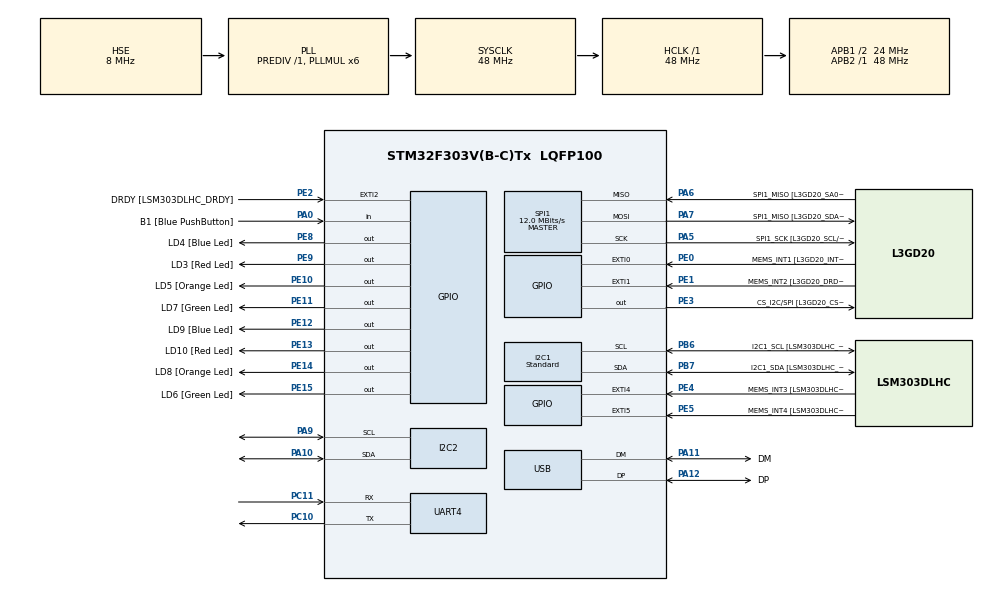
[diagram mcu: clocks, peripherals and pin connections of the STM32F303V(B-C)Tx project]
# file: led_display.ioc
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I2C1.Analog_Filter=I2C_ANALOGFILTER_DISABLE
I2C1.I2C_Speed_Mode=I2C_Standard
I2C1.Timing=0x00101D2D
I2C1.Timing-I2C=0x2000090E
I2C2.Analog_Filter=I2C_ANALOGFILTER_DISABLE
I2C2.Timing=0x00101D2D
Mcu.Family=STM32F3
Mcu.Name=STM32F303V(B-C)Tx
Mcu.Package=LQFP100
NVIC.PriorityGroup=NVIC_PRIORITYGROUP_0
PA0.GPIO_Label=B1 [Blue PushButton]
PA0.Signal=GPIO_Input
PA10.GPIO_Speed=GPIO_SPEED_FREQ_LOW
PA10.Mode=I2C
PA10.Signal=I2C2_SDA
PA11.GPIO_Label=DM
PA11.Mode=Device
PA11.Signal=USB_DM
PA12.GPIO_Label=DP
PA12.Mode=Device
PA12.Signal=USB_DP
PA13.GPIO_Label=SWDIO
PA13.Mode=Serial_Wire
PA13.Signal=SYS_JTMS-SWDIO
PA14.GPIO_Label=SWCLK
PA14.Mode=Serial_Wire
PA14.Signal=SYS_JTCK-SWCLK
PA5.GPIO_Label=SPI1_SCK [L3GD20_SCL/SPC]
PA5.Mode=Full_Duplex_Master
PA5.Signal=SPI1_SCK
PA6.GPIO_Label=SPI1_MISO [L3GD20_SA0/SDO]
PA6.Mode=Full_Duplex_Master
PA6.Signal=SPI1_MISO
PA7.GPIO_Label=SPI1_MISO [L3GD20_SDA/SDI/SDO]
PA7.Mode=Full_Duplex_Master
PA7.Signal=SPI1_MOSI
PA9.GPIO_Speed=GPIO_SPEED_FREQ_LOW
PA9.Mode=I2C
PA9.Signal=I2C2_SCL
PB3.GPIO_Label=SWO
PB3.Signal=SYS_JTDO-TRACESWO
PB6.GPIO_Label=I2C1_SCL [LSM303DLHC_SCL]
PB6.GPIO_Pu=GPIO_PULLUP
PB6.Mode=I2C
PB6.Signal=I2C1_SCL
PB7.GPIO_Label=I2C1_SDA [LSM303DLHC_SDA]
PB7.GPIO_Pu=GPIO_PULLUP
PB7.Mode=I2C
PB7.Signal=I2C1_SDA
PC10.Mode=Asynchronous
PC10.Signal=UART4_TX
PC11.Mode=Asynchronous
PC11.Signal=UART4_RX
PC14-OSC32_IN.GPIO_Label=OSC32_IN
PC14-OSC32_IN.Signal=RCC_OSC32_IN
PC15-OSC32_OUT.GPIO_Label=OSC32_OUT
PC15-OSC32_OUT.Signal=RCC_OSC32_OUT
PE0.GPIO_Label=MEMS_INT1 [L3GD20_INT1]
PE0.GPIO_ModeDefaultEXTI=GPIO_MODE_EVT_RISING
PE0.Signal=GPXTI0
PE1.GPIO_Label=MEMS_INT2 [L3GD20_DRDY/INT2]
PE1.GPIO_ModeDefaultEXTI=GPIO_MODE_EVT_RISING
PE1.Signal=GPXTI1
PE10.GPIO_Label=LD5 [Orange Led]
PE10.Signal=GPIO_Output
PE11.GPIO_Label=LD7 [Green Led]
PE11.Signal=GPIO_Output
PE12.GPIO_Label=LD9 [Blue Led]
PE12.Signal=GPIO_Output
PE13.GPIO_Label=LD10 [Red Led]
PE13.Signal=GPIO_Output
PE14.GPIO_Label=LD8 [Orange Led]
PE14.Signal=GPIO_Output
PE15.GPIO_Label=LD6 [Green Led]
PE15.Signal=GPIO_Output
PE2.GPIO_Label=DRDY [LSM303DLHC_DRDY]
PE2.GPIO_ModeDefaultEXTI=GPIO_MODE_EVT_RISING
PE2.Signal=GPXTI2
PE3.GPIO_Label=CS_I2C/SPI [L3GD20_CS_I2C/SPI]
PE3.Signal=GPIO_Output
PE4.GPIO_Label=MEMS_INT3 [LSM303DLHC_INT1]
PE4.GPIO_ModeDefaultEXTI=GPIO_MODE_EVT_RISING
PE4.Signal=GPXTI4
PE5.GPIO_Label=MEMS_INT4 [LSM303DLHC_INT2]
PE5.GPIO_ModeDefaultEXTI=GPIO_MODE_EVT_RISING
PE5.Signal=GPXTI5
PE8.GPIO_Label=LD4 [Blue Led]
PE8.Signal=GPIO_Output
PE9.GPIO_Label=LD3 [Red Led]
PE9.Signal=GPIO_Output
PF0-OSC_IN.GPIO_Label=OSC_IN
PF0-OSC_IN.Mode=HSE-External-Clock-Source
PF0-OSC_IN.Signal=RCC_OSC_IN
PF1-OSC_OUT.GPIO_Label=OSC_OUT
PF1-OSC_OUT.Signal=RCC_OSC_OUT
ProjectManager.HeapSize=0x200
ProjectManager.StackSize=0x400
ProjectManager.TargetToolchain=STM32CubeIDE
RCC.AHBFreq_Value=48000000
RCC.APB1CLKDivider=RCC_HCLK_DIV2
RCC.APB1Freq_Value=24000000
RCC.APB1TimFreq_Value=48000000
RCC.APB2Freq_Value=48000000
RCC.APB2TimFreq_Value=48000000
RCC.CortexFreq_Value=48000000
RCC.HCLKFreq_Value=48000000
RCC.HSE_VALUE=8000000
RCC.HSI_VALUE=8000000
RCC.LSE_VALUE=32768
RCC.PLLMUL=RCC_PLL_MUL6
RCC.SYSCLKFreq_VALUE=48000000
RCC.SYSCLKSourceVirtual=RCC_SYSCLKSOURCE_PLLCLK
RCC.USBFreq_Value=48000000
SPI1.BaudRatePrescaler=SPI_BAUDRATEPRESCALER_4
SPI1.BaudRatePrescaler-Full_Duplex_Master=SPI_BAUDRATEPRESCALER_2
SPI1.CalculateBaudRate=12.0 MBits/s
SPI1.CalculateBaudRate-Full_Duplex_Master=24.0 MBits/s
SPI1.Direction=SPI_DIRECTION_2LINES
SPI1.Mode=SPI_MODE_MASTER
SPI1.Mode-Full_Duplex_Master=SPI_MODE_MASTER
SPI1.VirtualType=VM_MASTER
board=STM32F3DISCOVERY

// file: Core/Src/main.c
/* USER CODE BEGIN Header */
/**
  ******************************************************************************
  * @file           : main.c
  * @brief          : Main program body
  ******************************************************************************
  * @attention
  *
  * Copyright (c) 2023 STMicroelectronics.
  * All rights reserved.
  *
  * This software is licensed under terms that can be found in the LICENSE file
  * in the root directory of this software component.
  * If no LICENSE file comes with this software, it is provided AS-IS.
  *
  ******************************************************************************
  */
/* USER CODE END Header */
#include "main.h"
#include "ssd1306.h"

I2C_HandleTypeDef hi2c1;
I2C_HandleTypeDef hi2c2;

SPI_HandleTypeDef hspi1;

UART_HandleTypeDef huart4;

PCD_HandleTypeDef hpcd_USB_FS;

/* USER CODE BEGIN PV */

int numFrame = 0;

const unsigned char nyancatframes[][512] = {{
0x00, 0x00, 0x00, 0x00, 0x00, 0x00, 0x00, 0x00, 0x00, 0x00, 0x00, 0x00, 0x00, 0x00, 0x00, 0x00,
0x00, 0x00, 0x00, 0x00, 0x00, 0x00, 0x00, 0x00, 0x00, 0x00, 0x00, 0x00, 0x00, 0x00, 0x00, 0x00,
0x00, 0x00, 0x00, 0x00, 0x00, 0x00, 0x00, 0x00, 0x00, 0x00, 0x00, 0x00, 0x00, 0x00, 0x00, 0x00,
0x00, 0x00, 0x00, 0x00, 0x00, 0x00, 0x00, 0x00, 0x00, 0x00, 0x00, 0x00, 0x00, 0x00, 0x00, 0x00,
0x00, 0x00, 0x00, 0x00, 0x00, 0x00, 0x00, 0x00, 0x00, 0x00, 0x00, 0x00, 0x00, 0x00, 0x00, 0x00,
0x00, 0x00, 0x00, 0x00, 0x00, 0x00, 0x00, 0x00, 0x00, 0x00, 0x00, 0x00, 0x00, 0x00, 0x00, 0x00,
0x3f, 0xc0, 0x3f, 0xc0, 0x3f, 0xc0, 0x3f, 0xc7, 0xff, 0xfc, 0x00, 0x00, 0x00, 0x00, 0x00, 0x00,
0xc0, 0x3f, 0xc0, 0x3f, 0xc0, 0x3f, 0xc0, 0x38, 0x00, 0x02, 0x00, 0x00, 0x00, 0x00, 0x00, 0x00,
0x00, 0x00, 0x00, 0x00, 0x00, 0x00, 0x00, 0x11, 0xff, 0xf1, 0x00, 0x00, 0x00, 0x00, 0x00, 0x00,
0x3f, 0xc0, 0x3f, 0xc0, 0x3f, 0xc0, 0x3f, 0xd2, 0x09, 0x09, 0x00, 0x00, 0x00, 0x00, 0x00, 0x00,
0xc0, 0x3f, 0xc0, 0x3f, 0xc0, 0x3f, 0xc0, 0x35, 0x00, 0x05, 0x00, 0x00, 0x00, 0x00, 0x00, 0x00,
0x00, 0x00, 0x00, 0x00, 0x00, 0x00, 0x00, 0x14, 0x01, 0x95, 0x60, 0x00, 0x00, 0x00, 0x00, 0x00,
0x3f, 0xc0, 0x3f, 0xc0, 0x3f, 0xc0, 0x3f, 0xd4, 0x02, 0x45, 0x90, 0x00, 0x00, 0x00, 0x00, 0x00,
0xc0, 0x3f, 0xc0, 0x3f, 0xc0, 0x3f, 0xc7, 0xb4, 0x12, 0x25, 0x10, 0x00, 0x00, 0x00, 0x00, 0x00,
0x00, 0x00, 0x00, 0x00, 0x00, 0x00, 0x04, 0xd4, 0x02, 0x1e, 0x10, 0x00, 0x00, 0x00, 0x00, 0x00,
0x3f, 0xc0, 0x3f, 0xc0, 0x3f, 0xc0, 0x3e, 0x74, 0x82, 0x00, 0x10, 0x00, 0x00, 0x00, 0x00, 0x00,
0xc0, 0x3f, 0xc0, 0x3f, 0xc0, 0x3f, 0xc3, 0x34, 0x0c, 0x00, 0x08, 0x00, 0x00, 0x00, 0x00, 0x00,
0x00, 0x00, 0x00, 0x00, 0x00, 0x00, 0x01, 0x96, 0x04, 0x20, 0x48, 0x00, 0x00, 0x00, 0x00, 0x00,
0x3f, 0xc0, 0x3f, 0xc0, 0x3f, 0xc0, 0x3f, 0xf4, 0x04, 0x62, 0xc8, 0x00, 0x00, 0x00, 0x00, 0x00,
0xc0, 0x3f, 0xc0, 0x3f, 0xc0, 0x3f, 0xc0, 0x34, 0x24, 0x00, 0x08, 0x00, 0x00, 0x00, 0x00, 0x00,
0x00, 0x00, 0x00, 0x00, 0x00, 0x00, 0x00, 0x13, 0x04, 0x24, 0x88, 0x00, 0x00, 0x00, 0x00, 0x00,
0x3f, 0xc0, 0x3f, 0xc0, 0x3f, 0xc0, 0x3f, 0xd1, 0xfe, 0x3f, 0x90, 0x00, 0x00, 0x00, 0x00, 0x00,
0xc0, 0x3f, 0xc0, 0x3f, 0xc0, 0x3f, 0xc0, 0x38, 0x01, 0x00, 0x20, 0x00, 0x00, 0x00, 0x00, 0x00,
0x00, 0x00, 0x00, 0x00, 0x00, 0x00, 0x00, 0x47, 0xff, 0xff, 0xc0, 0x00, 0x00, 0x00, 0x00, 0x00,
0x3f, 0xc0, 0x3f, 0xc0, 0x3f, 0xc0, 0x3f, 0xcf, 0x20, 0x94, 0x80, 0x00, 0x00, 0x00, 0x00, 0x00,
0xc0, 0x3f, 0xc0, 0x3f, 0xc0, 0x3f, 0xc0, 0x79, 0xc0, 0x73, 0x00, 0x00, 0x00, 0x00, 0x00, 0x00,
0x00, 0x00, 0x00, 0x00, 0x00, 0x00, 0x00, 0x00, 0x00, 0x00, 0x00, 0x00, 0x00, 0x00, 0x00, 0x00,
0x00, 0x00, 0x00, 0x00, 0x00, 0x00, 0x00, 0x00, 0x00, 0x00, 0x00, 0x00, 0x00, 0x00, 0x00, 0x00,
0x00, 0x00, 0x00, 0x00, 0x00, 0x00, 0x00, 0x00, 0x00, 0x00, 0x00, 0x00, 0x00, 0x00, 0x00, 0x00,
0x00, 0x00, 0x00, 0x00, 0x00, 0x00, 0x00, 0x00, 0x00, 0x00, 0x00, 0x00, 0x00, 0x00, 0x00, 0x00,
0x00, 0x00, 0x00, 0x00, 0x00, 0x00, 0x00, 0x00, 0x00, 0x00, 0x00, 0x00, 0x00, 0x00, 0x00, 0x00,
0x00, 0x00, 0x00, 0x00, 0x00, 0x00, 0x00, 0x00, 0x00, 0x00, 0x00, 0x00, 0x00, 0x00, 0x00, 0x00
},{
0x00, 0x00, 0x00, 0x00, 0x00, 0x00, 0x00, 0x00, 0x00, 0x00, 0x00, 0x00, 0x00, 0x00, 0x00, 0x00,
0x00, 0x00, 0x00, 0x00, 0x00, 0x00, 0x00, 0x00, 0x00, 0x00, 0x00, 0x00, 0x00, 0x00, 0x00, 0x00,
0x00, 0x00, 0x00, 0x00, 0x00, 0x00, 0x00, 0x00, 0x00, 0x00, 0x00, 0x00, 0x00, 0x00, 0x00, 0x00,
0x00, 0x00, 0x00, 0x00, 0x00, 0x00, 0x00, 0x00, 0x00, 0x00, 0x00, 0x00, 0x00, 0x00, 0x00, 0x00,
0x00, 0x00, 0x00, 0x00, 0x00, 0x00, 0x00, 0x00, 0x00, 0x00, 0x00, 0x00, 0x00, 0x00, 0x00, 0x00,
0x00, 0x00, 0x00, 0x00, 0x00, 0x00, 0x00, 0x00, 0x00, 0x00, 0x00, 0x00, 0x00, 0x00, 0x00, 0x00,
0x7f, 0x80, 0x7f, 0x80, 0x7f, 0x80, 0x7f, 0x87, 0xff, 0xfc, 0x00, 0x00, 0x00, 0x00, 0x00, 0x00,
0x80, 0x7f, 0x80, 0x7f, 0x80, 0x7f, 0x80, 0x78, 0x00, 0x02, 0x00, 0x00, 0x00, 0x00, 0x00, 0x00,
0x00, 0x00, 0x00, 0x00, 0x00, 0x00, 0x00, 0x11, 0xff, 0xf1, 0x00, 0x00, 0x00, 0x00, 0x00, 0x00,
0x7f, 0x80, 0x7f, 0x80, 0x7f, 0x80, 0x7f, 0x92, 0x09, 0x09, 0x00, 0x00, 0x00, 0x00, 0x00, 0x00,
0x80, 0x7f, 0x80, 0x7f, 0x80, 0x7f, 0x80, 0x75, 0x00, 0x05, 0x00, 0x00, 0x00, 0x00, 0x00, 0x00,
0x00, 0x00, 0x00, 0x00, 0x00, 0x00, 0x00, 0x14, 0x00, 0xd5, 0x30, 0x00, 0x00, 0x00, 0x00, 0x00,
0x7f, 0x80, 0x7f, 0x80, 0x7f, 0x80, 0x7f, 0x94, 0x01, 0x25, 0x48, 0x00, 0x00, 0x00, 0x00, 0x00,
0x80, 0x7f, 0x80, 0x7f, 0x80, 0x7f, 0x80, 0x74, 0x11, 0x15, 0x88, 0x00, 0x00, 0x00, 0x00, 0x00,
0x00, 0x00, 0x00, 0x00, 0x00, 0x00, 0x03, 0x14, 0x01, 0x0f, 0x08, 0x00, 0x00, 0x00, 0x00, 0x00,
0x7f, 0x80, 0x7f, 0x80, 0x7f, 0x80, 0x7c, 0x94, 0x81, 0x00, 0x08, 0x00, 0x00, 0x00, 0x00, 0x00,
0x80, 0x7f, 0x80, 0x7f, 0x80, 0x7f, 0x84, 0xf4, 0x0a, 0x00, 0x04, 0x00, 0x00, 0x00, 0x00, 0x00,
0x00, 0x00, 0x00, 0x00, 0x00, 0x00, 0x02, 0x16, 0x02, 0x10, 0x24, 0x00, 0x00, 0x00, 0x00, 0x00,
0x7f, 0x80, 0x7f, 0x80, 0x7f, 0x80, 0x7f, 0x94, 0x02, 0x31, 0x64, 0x00, 0x00, 0x00, 0x00, 0x00,
0x80, 0x7f, 0x80, 0x7f, 0x80, 0x7f, 0x80, 0x74, 0x22, 0x00, 0x04, 0x00, 0x00, 0x00, 0x00, 0x00,
0x00, 0x00, 0x00, 0x00, 0x00, 0x00, 0x00, 0x13, 0x02, 0x12, 0x44, 0x00, 0x00, 0x00, 0x00, 0x00,
0x7f, 0x80, 0x7f, 0x80, 0x7f, 0x80, 0x7f, 0x91, 0xff, 0x1f, 0xc8, 0x00, 0x00, 0x00, 0x00, 0x00,
0x80, 0x7f, 0x80, 0x7f, 0x80, 0x7f, 0x80, 0x78, 0x00, 0x80, 0x10, 0x00, 0x00, 0x00, 0x00, 0x00,
0x00, 0x00, 0x00, 0x00, 0x00, 0x00, 0x00, 0x27, 0xff, 0xff, 0xe0, 0x00, 0x00, 0x00, 0x00, 0x00,
0x7f, 0x80, 0x7f, 0x80, 0x7f, 0x80, 0x7f, 0xa5, 0x20, 0x4a, 0x40, 0x00, 0x00, 0x00, 0x00, 0x00,
0x80, 0x7f, 0x80, 0x7f, 0x80, 0x7f, 0x80, 0x7e, 0xe0, 0x39, 0xc0, 0x00, 0x00, 0x00, 0x00, 0x00,
0x00, 0x00, 0x00, 0x00, 0x00, 0x00, 0x00, 0x00, 0x00, 0x00, 0x00, 0x00, 0x00, 0x00, 0x00, 0x00,
0x00, 0x00, 0x00, 0x00, 0x00, 0x00, 0x00, 0x00, 0x00, 0x00, 0x00, 0x00, 0x00, 0x00, 0x00, 0x00,
0x00, 0x00, 0x00, 0x00, 0x00, 0x00, 0x00, 0x00, 0x00, 0x00, 0x00, 0x00, 0x00, 0x00, 0x00, 0x00,
0x00, 0x00, 0x00, 0x00, 0x00, 0x00, 0x00, 0x00, 0x00, 0x00, 0x00, 0x00, 0x00, 0x00, 0x00, 0x00,
0x00, 0x00, 0x00, 0x00, 0x00, 0x00, 0x00, 0x00, 0x00, 0x00, 0x00, 0x00, 0x00, 0x00, 0x00, 0x00,
0x00, 0x00, 0x00, 0x00, 0x00, 0x00, 0x00, 0x00, 0x00, 0x00, 0x00, 0x00, 0x00, 0x00, 0x00, 0x00
},{
0x00, 0x00, 0x00, 0x00, 0x00, 0x00, 0x00, 0x00, 0x00, 0x00, 0x00, 0x00, 0x00, 0x00, 0x00, 0x00,
0x00, 0x00, 0x00, 0x00, 0x00, 0x00, 0x00, 0x00, 0x00, 0x00, 0x00, 0x00, 0x00, 0x00, 0x00, 0x00,
0x00, 0x00, 0x00, 0x00, 0x00, 0x00, 0x00, 0x00, 0x00, 0x00, 0x00, 0x00, 0x00, 0x00, 0x00, 0x00,
0x00, 0x00, 0x00, 0x00, 0x00, 0x00, 0x00, 0x00, 0x00, 0x00, 0x00, 0x00, 0x00, 0x00, 0x00, 0x00,
0x00, 0x00, 0x00, 0x00, 0x00, 0x00, 0x00, 0x00, 0x00, 0x00, 0x00, 0x00, 0x00, 0x00, 0x00, 0x00,
0x00, 0x00, 0x00, 0x00, 0x00, 0x00, 0x00, 0x00, 0x00, 0x00, 0x00, 0x00, 0x00, 0x00, 0x00, 0x00,
0xc0, 0x3f, 0xc0, 0x3f, 0xc0, 0x3f, 0xc0, 0x3f, 0xc0, 0x00, 0x00, 0x00, 0x00, 0x00, 0x00, 0x00,
0x3f, 0xc0, 0x3f, 0xc0, 0x3f, 0xc0, 0x3f, 0xc7, 0xff, 0xfc, 0x00, 0x00, 0x00, 0x00, 0x00, 0x00,
0x00, 0x00, 0x00, 0x00, 0x00, 0x00, 0x00, 0x08, 0x00, 0x02, 0x00, 0x00, 0x00, 0x00, 0x00, 0x00,
0xc0, 0x3f, 0xc0, 0x3f, 0xc0, 0x3f, 0xc0, 0x31, 0xff, 0xf1, 0x00, 0x00, 0x00, 0x00, 0x00, 0x00,
0x3f, 0xc0, 0x3f, 0xc0, 0x3f, 0xc0, 0x3f, 0xd2, 0x09, 0x09, 0x00, 0x00, 0x00, 0x00, 0x00, 0x00,
0x00, 0x00, 0x00, 0x00, 0x00, 0x00, 0x00, 0x15, 0x00, 0x05, 0x00, 0x00, 0x00, 0x00, 0x00, 0x00,
0xc0, 0x3f, 0xc0, 0x3f, 0xc0, 0x3f, 0xc0, 0x34, 0x00, 0xd5, 0x30, 0x00, 0x00, 0x00, 0x00, 0x00,
0x3f, 0xc0, 0x3f, 0xc0, 0x3f, 0xc0, 0x3f, 0xd4, 0x01, 0x25, 0x48, 0x00, 0x00, 0x00, 0x00, 0x00,
0x00, 0x00, 0x00, 0x00, 0x00, 0x00, 0x00, 0x14, 0x11, 0x15, 0x88, 0x00, 0x00, 0x00, 0x00, 0x00,
0xc0, 0x3f, 0xc0, 0x3f, 0xc0, 0x3f, 0xc0, 0x34, 0x01, 0x0f, 0x08, 0x00, 0x00, 0x00, 0x00, 0x00,
0x3f, 0xc0, 0x3f, 0xc0, 0x3f, 0xc0, 0x3f, 0xd4, 0x81, 0x00, 0x08, 0x00, 0x00, 0x00, 0x00, 0x00,
0x00, 0x00, 0x00, 0x00, 0x00, 0x00, 0x00, 0x34, 0x0a, 0x00, 0x04, 0x00, 0x00, 0x00, 0x00, 0x00,
0xc0, 0x3f, 0xc0, 0x3f, 0xc0, 0x3f, 0xc1, 0xf6, 0x02, 0x10, 0x24, 0x00, 0x00, 0x00, 0x00, 0x00,
0x3f, 0xc0, 0x3f, 0xc0, 0x3f, 0xc0, 0x3e, 0x14, 0x02, 0x31, 0x64, 0x00, 0x00, 0x00, 0x00, 0x00,
0x00, 0x00, 0x00, 0x00, 0x00, 0x00, 0x04, 0x74, 0x22, 0x00, 0x04, 0x00, 0x00, 0x00, 0x00, 0x00,
0xc0, 0x3f, 0xc0, 0x3f, 0xc0, 0x3f, 0xc3, 0xf3, 0x02, 0x12, 0x44, 0x00, 0x00, 0x00, 0x00, 0x00,
0x3f, 0xc0, 0x3f, 0xc0, 0x3f, 0xc0, 0x3f, 0xd1, 0xff, 0x1f, 0xc8, 0x00, 0x00, 0x00, 0x00, 0x00,
0x00, 0x00, 0x00, 0x00, 0x00, 0x00, 0x00, 0x18, 0x00, 0x80, 0x10, 0x00, 0x00, 0x00, 0x00, 0x00,
0xc0, 0x3f, 0xc0, 0x3f, 0xc0, 0x3f, 0xc0, 0x37, 0xff, 0xff, 0xe0, 0x00, 0x00, 0x00, 0x00, 0x00,
0x3f, 0xc0, 0x3f, 0xc0, 0x3f, 0xc0, 0x3f, 0xd2, 0x90, 0x25, 0x20, 0x00, 0x00, 0x00, 0x00, 0x00,
0x00, 0x00, 0x00, 0x00, 0x00, 0x00, 0x00, 0x1c, 0x70, 0x1c, 0xe0, 0x00, 0x00, 0x00, 0x00, 0x00,
0x00, 0x00, 0x00, 0x00, 0x00, 0x00, 0x00, 0x00, 0x00, 0x00, 0x00, 0x00, 0x00, 0x00, 0x00, 0x00,
0x00, 0x00, 0x00, 0x00, 0x00, 0x00, 0x00, 0x00, 0x00, 0x00, 0x00, 0x00, 0x00, 0x00, 0x00, 0x00,
0x00, 0x00, 0x00, 0x00, 0x00, 0x00, 0x00, 0x00, 0x00, 0x00, 0x00, 0x00, 0x00, 0x00, 0x00, 0x00,
0x00, 0x00, 0x00, 0x00, 0x00, 0x00, 0x00, 0x00, 0x00, 0x00, 0x00, 0x00, 0x00, 0x00, 0x00, 0x00,
0x00, 0x00, 0x00, 0x00, 0x00, 0x00, 0x00, 0x00, 0x00, 0x00, 0x00, 0x00, 0x00, 0x00, 0x00, 0x00
},{
0x00, 0x00, 0x00, 0x00, 0x00, 0x00, 0x00, 0x00, 0x00, 0x00, 0x00, 0x00, 0x00, 0x00, 0x00, 0x00,
0x00, 0x00, 0x00, 0x00, 0x00, 0x00, 0x00, 0x00, 0x00, 0x00, 0x00, 0x00, 0x00, 0x00, 0x00, 0x00,
0x00, 0x00, 0x00, 0x00, 0x00, 0x00, 0x00, 0x00, 0x00, 0x00, 0x00, 0x00, 0x00, 0x00, 0x00, 0x00,
0x00, 0x00, 0x00, 0x00, 0x00, 0x00, 0x00, 0x00, 0x00, 0x00, 0x00, 0x00, 0x00, 0x00, 0x00, 0x00,
0x00, 0x00, 0x00, 0x00, 0x00, 0x00, 0x00, 0x00, 0x00, 0x00, 0x00, 0x00, 0x00, 0x00, 0x00, 0x00,
0x00, 0x00, 0x00, 0x00, 0x00, 0x00, 0x00, 0x00, 0x00, 0x00, 0x00, 0x00, 0x00, 0x00, 0x00, 0x00,
0xc0, 0x3f, 0xc0, 0x3f, 0xc0, 0x3f, 0xc0, 0x3f, 0xc0, 0x00, 0x00, 0x00, 0x00, 0x00, 0x00, 0x00,
0x3f, 0xc0, 0x3f, 0xc0, 0x3f, 0xc0, 0x3f, 0xc7, 0xff, 0xfc, 0x00, 0x00, 0x00, 0x00, 0x00, 0x00,
0x00, 0x00, 0x00, 0x00, 0x00, 0x00, 0x00, 0x08, 0x00, 0x02, 0x00, 0x00, 0x00, 0x00, 0x00, 0x00,
0xc0, 0x3f, 0xc0, 0x3f, 0xc0, 0x3f, 0xc0, 0x31, 0xff, 0xf1, 0x00, 0x00, 0x00, 0x00, 0x00, 0x00,
0x3f, 0xc0, 0x3f, 0xc0, 0x3f, 0xc0, 0x3f, 0xd2, 0x09, 0x09, 0x00, 0x00, 0x00, 0x00, 0x00, 0x00,
0x00, 0x00, 0x00, 0x00, 0x00, 0x00, 0x00, 0x15, 0x00, 0x05, 0x00, 0x00, 0x00, 0x00, 0x00, 0x00,
0xc0, 0x3f, 0xc0, 0x3f, 0xc0, 0x3f, 0xc0, 0x34, 0x00, 0xd5, 0x30, 0x00, 0x00, 0x00, 0x00, 0x00,
0x3f, 0xc0, 0x3f, 0xc0, 0x3f, 0xc0, 0x3f, 0xd4, 0x01, 0x25, 0x48, 0x00, 0x00, 0x00, 0x00, 0x00,
0x00, 0x00, 0x00, 0x00, 0x00, 0x00, 0x00, 0x14, 0x11, 0x15, 0x88, 0x00, 0x00, 0x00, 0x00, 0x00,
0xc0, 0x3f, 0xc0, 0x3f, 0xc0, 0x3f, 0xc0, 0x34, 0x01, 0x0f, 0x08, 0x00, 0x00, 0x00, 0x00, 0x00,
0x3f, 0xc0, 0x3f, 0xc0, 0x3f, 0xc0, 0x3f, 0xd4, 0x81, 0x00, 0x08, 0x00, 0x00, 0x00, 0x00, 0x00,
0x00, 0x00, 0x00, 0x00, 0x00, 0x00, 0x00, 0x34, 0x0a, 0x00, 0x04, 0x00, 0x00, 0x00, 0x00, 0x00,
0xc0, 0x3f, 0xc0, 0x3f, 0xc0, 0x3f, 0xc1, 0xf6, 0x02, 0x10, 0x24, 0x00, 0x00, 0x00, 0x00, 0x00,
0x3f, 0xc0, 0x3f, 0xc0, 0x3f, 0xc0, 0x3e, 0x14, 0x02, 0x31, 0x64, 0x00, 0x00, 0x00, 0x00, 0x00,
0x00, 0x00, 0x00, 0x00, 0x00, 0x00, 0x04, 0x74, 0x22, 0x00, 0x04, 0x00, 0x00, 0x00, 0x00, 0x00,
0xc0, 0x3f, 0xc0, 0x3f, 0xc0, 0x3f, 0xc3, 0xf3, 0x02, 0x12, 0x44, 0x00, 0x00, 0x00, 0x00, 0x00,
0x3f, 0xc0, 0x3f, 0xc0, 0x3f, 0xc0, 0x3f, 0xd1, 0xff, 0x1f, 0xc8, 0x00, 0x00, 0x00, 0x00, 0x00,
0x00, 0x00, 0x00, 0x00, 0x00, 0x00, 0x00, 0x18, 0x00, 0x80, 0x10, 0x00, 0x00, 0x00, 0x00, 0x00,
0xc0, 0x3f, 0xc0, 0x3f, 0xc0, 0x3f, 0xc0, 0x37, 0xff, 0xff, 0xe0, 0x00, 0x00, 0x00, 0x00, 0x00,
0x3f, 0xc0, 0x3f, 0xc0, 0x3f, 0xc0, 0x3f, 0xd2, 0x90, 0x25, 0x20, 0x00, 0x00, 0x00, 0x00, 0x00,
0x00, 0x00, 0x00, 0x00, 0x00, 0x00, 0x00, 0x1c, 0x70, 0x1c, 0xe0, 0x00, 0x00, 0x00, 0x00, 0x00,
0x00, 0x00, 0x00, 0x00, 0x00, 0x00, 0x00, 0x00, 0x00, 0x00, 0x00, 0x00, 0x00, 0x00, 0x00, 0x00,
0x00, 0x00, 0x00, 0x00, 0x00, 0x00, 0x00, 0x00, 0x00, 0x00, 0x00, 0x00, 0x00, 0x00, 0x00, 0x00,
0x00, 0x00, 0x00, 0x00, 0x00, 0x00, 0x00, 0x00, 0x00, 0x00, 0x00, 0x00, 0x00, 0x00, 0x00, 0x00,
0x00, 0x00, 0x00, 0x00, 0x00, 0x00, 0x00, 0x00, 0x00, 0x00, 0x00, 0x00, 0x00, 0x00, 0x00, 0x00,
0x00, 0x00, 0x00, 0x00, 0x00, 0x00, 0x00, 0x00, 0x00, 0x00, 0x00, 0x00, 0x00, 0x00, 0x00, 0x00
},{
0x00, 0x00, 0x00, 0x00, 0x00, 0x00, 0x00, 0x00, 0x00, 0x00, 0x00, 0x00, 0x00, 0x00, 0x00, 0x00,
0x00, 0x00, 0x00, 0x00, 0x00, 0x00, 0x00, 0x00, 0x00, 0x00, 0x00, 0x00, 0x00, 0x00, 0x00, 0x00,
0x00, 0x00, 0x00, 0x00, 0x00, 0x00, 0x00, 0x00, 0x00, 0x00, 0x00, 0x00, 0x00, 0x00, 0x00, 0x00,
0x00, 0x00, 0x00, 0x00, 0x00, 0x00, 0x00, 0x00, 0x00, 0x00, 0x00, 0x00, 0x00, 0x00, 0x00, 0x00,
0x00, 0x00, 0x00, 0x00, 0x00, 0x00, 0x00, 0x00, 0x00, 0x00, 0x00, 0x00, 0x00, 0x00, 0x00, 0x00,
0x00, 0x00, 0x00, 0x00, 0x00, 0x00, 0x00, 0x00, 0x00, 0x00, 0x00, 0x00, 0x00, 0x00, 0x00, 0x00,
0x3f, 0xc0, 0x3f, 0xc0, 0x3f, 0xc0, 0x3f, 0xc0, 0x00, 0x00, 0x00, 0x00, 0x00, 0x00, 0x00, 0x00,
0xc0, 0x3f, 0xc0, 0x3f, 0xc0, 0x3f, 0xc0, 0x3f, 0xff, 0xfc, 0x00, 0x00, 0x00, 0x00, 0x00, 0x00,
0x00, 0x00, 0x00, 0x00, 0x00, 0x00, 0x00, 0x08, 0x00, 0x02, 0x00, 0x00, 0x00, 0x00, 0x00, 0x00,
0x3f, 0xc0, 0x3f, 0xc0, 0x3f, 0xc0, 0x3f, 0xd1, 0xff, 0xf1, 0x00, 0x00, 0x00, 0x00, 0x00, 0x00,
0xc0, 0x3f, 0xc0, 0x3f, 0xc0, 0x3f, 0xc0, 0x32, 0x09, 0x09, 0x00, 0x00, 0x00, 0x00, 0x00, 0x00,
0x00, 0x00, 0x00, 0x00, 0x00, 0x00, 0x00, 0x15, 0x00, 0x05, 0x00, 0x00, 0x00, 0x00, 0x00, 0x00,
0x3f, 0xc0, 0x3f, 0xc0, 0x3f, 0xc0, 0x3f, 0xd4, 0x01, 0x95, 0x60, 0x00, 0x00, 0x00, 0x00, 0x00,
0xc0, 0x3f, 0xc0, 0x3f, 0xc0, 0x3f, 0xc0, 0x34, 0x02, 0x45, 0x90, 0x00, 0x00, 0x00, 0x00, 0x00,
0x00, 0x00, 0x00, 0x00, 0x00, 0x00, 0x00, 0x14, 0x12, 0x25, 0x10, 0x00, 0x00, 0x00, 0x00, 0x00,
0x3f, 0xc0, 0x3f, 0xc0, 0x3f, 0xc0, 0x3f, 0xd4, 0x02, 0x1e, 0x10, 0x00, 0x00, 0x00, 0x00, 0x00,
0xc0, 0x3f, 0xc0, 0x3f, 0xc0, 0x3f, 0xc8, 0xf4, 0x82, 0x00, 0x10, 0x00, 0x00, 0x00, 0x00, 0x00,
0x00, 0x00, 0x00, 0x00, 0x00, 0x00, 0x0c, 0x34, 0x0c, 0x00, 0x08, 0x00, 0x00, 0x00, 0x00, 0x00,
0x3f, 0xc0, 0x3f, 0xc0, 0x3f, 0xc0, 0x3f, 0xd6, 0x04, 0x20, 0x48, 0x00, 0x00, 0x00, 0x00, 0x00,
0xc0, 0x3f, 0xc0, 0x3f, 0xc0, 0x3f, 0xc0, 0x74, 0x04, 0x62, 0xc8, 0x00, 0x00, 0x00, 0x00, 0x00,
0x00, 0x00, 0x00, 0x00, 0x00, 0x00, 0x00, 0x14, 0x24, 0x00, 0x08, 0x00, 0x00, 0x00, 0x00, 0x00,
0x3f, 0xc0, 0x3f, 0xc0, 0x3f, 0xc0, 0x3f, 0xd3, 0x04, 0x24, 0x88, 0x00, 0x00, 0x00, 0x00, 0x00,
0xc0, 0x3f, 0xc0, 0x3f, 0xc0, 0x3f, 0xc0, 0x31, 0xfe, 0x3f, 0x90, 0x00, 0x00, 0x00, 0x00, 0x00,
0x00, 0x00, 0x00, 0x00, 0x00, 0x00, 0x00, 0x78, 0x01, 0x00, 0x20, 0x00, 0x00, 0x00, 0x00, 0x00,
0x3f, 0xc0, 0x3f, 0xc0, 0x3f, 0xc0, 0x3f, 0x8f, 0xff, 0xff, 0xc0, 0x00, 0x00, 0x00, 0x00, 0x00,
0xc0, 0x3f, 0xc0, 0x3f, 0xc0, 0x3f, 0xc0, 0x94, 0x81, 0x29, 0x00, 0x00, 0x00, 0x00, 0x00, 0x00,
0x00, 0x00, 0x00, 0x00, 0x00, 0x00, 0x00, 0xe3, 0x80, 0xe7, 0x00, 0x00, 0x00, 0x00, 0x00, 0x00,
0x00, 0x00, 0x00, 0x00, 0x00, 0x00, 0x00, 0x00, 0x00, 0x00, 0x00, 0x00, 0x00, 0x00, 0x00, 0x00,
0x00, 0x00, 0x00, 0x00, 0x00, 0x00, 0x00, 0x00, 0x00, 0x00, 0x00, 0x00, 0x00, 0x00, 0x00, 0x00,
0x00, 0x00, 0x00, 0x00, 0x00, 0x00, 0x00, 0x00, 0x00, 0x00, 0x00, 0x00, 0x00, 0x00, 0x00, 0x00,
0x00, 0x00, 0x00, 0x00, 0x00, 0x00, 0x00, 0x00, 0x00, 0x00, 0x00, 0x00, 0x00, 0x00, 0x00, 0x00,
0x00, 0x00, 0x00, 0x00, 0x00, 0x00, 0x00, 0x00, 0x00, 0x00, 0x00, 0x00, 0x00, 0x00, 0x00, 0x00
},{
0x00, 0x00, 0x00, 0x00, 0x00, 0x00, 0x00, 0x00, 0x00, 0x00, 0x00, 0x00, 0x00, 0x00, 0x00, 0x00,
0x00, 0x00, 0x00, 0x00, 0x00, 0x00, 0x00, 0x00, 0x00, 0x00, 0x00, 0x00, 0x00, 0x00, 0x00, 0x00,
0x00, 0x00, 0x00, 0x00, 0x00, 0x00, 0x00, 0x00, 0x00, 0x00, 0x00, 0x00, 0x00, 0x00, 0x00, 0x00,
0x00, 0x00, 0x00, 0x00, 0x00, 0x00, 0x00, 0x00, 0x00, 0x00, 0x00, 0x00, 0x00, 0x00, 0x00, 0x00,
0x00, 0x00, 0x00, 0x00, 0x00, 0x00, 0x00, 0x00, 0x00, 0x00, 0x00, 0x00, 0x00, 0x00, 0x00, 0x00,
0x00, 0x00, 0x00, 0x00, 0x00, 0x00, 0x00, 0x00, 0x00, 0x00, 0x00, 0x00, 0x00, 0x00, 0x00, 0x00,
0x7f, 0x80, 0x7f, 0x80, 0x7f, 0x80, 0x7f, 0x80, 0x00, 0x00, 0x00, 0x00, 0x00, 0x00, 0x00, 0x00,
0x80, 0x7f, 0x80, 0x7f, 0x80, 0x7f, 0x80, 0x7f, 0xff, 0xfc, 0x00, 0x00, 0x00, 0x00, 0x00, 0x00,
0x00, 0x00, 0x00, 0x00, 0x00, 0x00, 0x00, 0x08, 0x00, 0x02, 0x00, 0x00, 0x00, 0x00, 0x00, 0x00,
0x7f, 0x80, 0x7f, 0x80, 0x7f, 0x80, 0x7f, 0x91, 0xff, 0xf1, 0x00, 0x00, 0x00, 0x00, 0x00, 0x00,
0x80, 0x7f, 0x80, 0x7f, 0x80, 0x7f, 0x80, 0x72, 0x09, 0x09, 0x00, 0x00, 0x00, 0x00, 0x00, 0x00,
0x00, 0x00, 0x00, 0x00, 0x00, 0x00, 0x00, 0x15, 0x01, 0x85, 0x60, 0x00, 0x00, 0x00, 0x00, 0x00,
0x7f, 0x80, 0x7f, 0x80, 0x7f, 0x80, 0x7f, 0x94, 0x02, 0x55, 0x90, 0x00, 0x00, 0x00, 0x00, 0x00,
0x80, 0x7f, 0x80, 0x7f, 0x80, 0x7f, 0x80, 0x74, 0x02, 0x25, 0x10, 0x00, 0x00, 0x00, 0x00, 0x00,
0x00, 0x00, 0x00, 0x00, 0x00, 0x00, 0x03, 0x14, 0x12, 0x1e, 0x10, 0x00, 0x00, 0x00, 0x00, 0x00,
0x7f, 0x80, 0x7f, 0x80, 0x7f, 0x80, 0x7c, 0x94, 0x02, 0x00, 0x10, 0x00, 0x00, 0x00, 0x00, 0x00,
0x80, 0x7f, 0x80, 0x7f, 0x80, 0x7f, 0x84, 0xf4, 0x84, 0x00, 0x08, 0x00, 0x00, 0x00, 0x00, 0x00,
0x00, 0x00, 0x00, 0x00, 0x00, 0x00, 0x02, 0x14, 0x0c, 0x20, 0x48, 0x00, 0x00, 0x00, 0x00, 0x00,
0x7f, 0x80, 0x7f, 0x80, 0x7f, 0x80, 0x7f, 0x96, 0x04, 0x62, 0xc8, 0x00, 0x00, 0x00, 0x00, 0x00,
0x80, 0x7f, 0x80, 0x7f, 0x80, 0x7f, 0x80, 0x74, 0x04, 0x00, 0x08, 0x00, 0x00, 0x00, 0x00, 0x00,
0x00, 0x00, 0x00, 0x00, 0x00, 0x00, 0x00, 0x14, 0x24, 0x24, 0x88, 0x00, 0x00, 0x00, 0x00, 0x00,
0x7f, 0x80, 0x7f, 0x80, 0x7f, 0x80, 0x7f, 0x93, 0x02, 0x3f, 0x90, 0x00, 0x00, 0x00, 0x00, 0x00,
0x80, 0x7f, 0x80, 0x7f, 0x80, 0x7f, 0x80, 0x71, 0xff, 0x00, 0x20, 0x00, 0x00, 0x00, 0x00, 0x00,
0x00, 0x00, 0x00, 0x00, 0x00, 0x00, 0x00, 0x58, 0x00, 0xff, 0xc0, 0x00, 0x00, 0x00, 0x00, 0x00,
0x7f, 0x80, 0x7f, 0x80, 0x7f, 0x80, 0x7f, 0x8f, 0xff, 0xfd, 0x00, 0x00, 0x00, 0x00, 0x00, 0x00,
0x80, 0x7f, 0x80, 0x7f, 0x80, 0x7f, 0x80, 0x94, 0x81, 0x29, 0x00, 0x00, 0x00, 0x00, 0x00, 0x00,
0x00, 0x00, 0x00, 0x00, 0x00, 0x00, 0x00, 0xe7, 0x01, 0xc7, 0x00, 0x00, 0x00, 0x00, 0x00, 0x00,
0x00, 0x00, 0x00, 0x00, 0x00, 0x00, 0x00, 0x00, 0x00, 0x00, 0x00, 0x00, 0x00, 0x00, 0x00, 0x00,
0x00, 0x00, 0x00, 0x00, 0x00, 0x00, 0x00, 0x00, 0x00, 0x00, 0x00, 0x00, 0x00, 0x00, 0x00, 0x00,
0x00, 0x00, 0x00, 0x00, 0x00, 0x00, 0x00, 0x00, 0x00, 0x00, 0x00, 0x00, 0x00, 0x00, 0x00, 0x00,
0x00, 0x00, 0x00, 0x00, 0x00, 0x00, 0x00, 0x00, 0x00, 0x00, 0x00, 0x00, 0x00, 0x00, 0x00, 0x00,
0x00, 0x00, 0x00, 0x00, 0x00, 0x00, 0x00, 0x00, 0x00, 0x00, 0x00, 0x00, 0x00, 0x00, 0x00, 0x00
},{
0x00, 0x00, 0x00, 0x00, 0x00, 0x00, 0x00, 0x00, 0x00, 0x00, 0x00, 0x00, 0x00, 0x00, 0x00, 0x00,
0x00, 0x00, 0x00, 0x00, 0x00, 0x00, 0x00, 0x00, 0x00, 0x00, 0x00, 0x00, 0x00, 0x00, 0x00, 0x00,
0x00, 0x00, 0x00, 0x00, 0x00, 0x00, 0x00, 0x00, 0x00, 0x00, 0x00, 0x00, 0x00, 0x00, 0x00, 0x00,
0x00, 0x00, 0x00, 0x00, 0x00, 0x00, 0x00, 0x00, 0x00, 0x00, 0x00, 0x00, 0x00, 0x00, 0x00, 0x00,
0x00, 0x00, 0x00, 0x00, 0x00, 0x00, 0x00, 0x00, 0x00, 0x00, 0x00, 0x00, 0x00, 0x00, 0x00, 0x00,
0x00, 0x00, 0x00, 0x00, 0x00, 0x00, 0x00, 0x00, 0x00, 0x00, 0x00, 0x00, 0x00, 0x00, 0x00, 0x00,
0xc0, 0x3f, 0xc0, 0x3f, 0xc0, 0x3f, 0xc0, 0x3f, 0xff, 0xfc, 0x00, 0x00, 0x00, 0x00, 0x00, 0x00,
0x3f, 0xc0, 0x3f, 0xc0, 0x3f, 0xc0, 0x3f, 0xc8, 0x00, 0x02, 0x00, 0x00, 0x00, 0x00, 0x00, 0x00,
0x00, 0x00, 0x00, 0x00, 0x00, 0x00, 0x00, 0x11, 0xff, 0xf1, 0x00, 0x00, 0x00, 0x00, 0x00, 0x00,
0xc0, 0x3f, 0xc0, 0x3f, 0xc0, 0x3f, 0xc0, 0x32, 0x09, 0x09, 0x00, 0x00, 0x00, 0x00, 0x00, 0x00,
0x3f, 0xc0, 0x3f, 0xc0, 0x3f, 0xc0, 0x3f, 0xd5, 0x00, 0x05, 0x00, 0x00, 0x00, 0x00, 0x00, 0x00,
0x00, 0x00, 0x00, 0x00, 0x00, 0x00, 0x00, 0x14, 0x01, 0x95, 0x60, 0x00, 0x00, 0x00, 0x00, 0x00,
0xc0, 0x3f, 0xc0, 0x3f, 0xc0, 0x3f, 0xc0, 0x34, 0x02, 0x45, 0x90, 0x00, 0x00, 0x00, 0x00, 0x00,
0x3f, 0xc0, 0x3f, 0xc0, 0x3f, 0xc0, 0x3f, 0xd4, 0x12, 0x25, 0x10, 0x00, 0x00, 0x00, 0x00, 0x00,
0x00, 0x00, 0x00, 0x00, 0x00, 0x00, 0x04, 0xd4, 0x02, 0x1e, 0x10, 0x00, 0x00, 0x00, 0x00, 0x00,
0xc0, 0x3f, 0xc0, 0x3f, 0xc0, 0x3f, 0xc6, 0x74, 0x82, 0x00, 0x10, 0x00, 0x00, 0x00, 0x00, 0x00,
0x3f, 0xc0, 0x3f, 0xc0, 0x3f, 0xc0, 0x3f, 0x34, 0x0c, 0x00, 0x08, 0x00, 0x00, 0x00, 0x00, 0x00,
0x00, 0x00, 0x00, 0x00, 0x00, 0x00, 0x01, 0x96, 0x04, 0x20, 0x48, 0x00, 0x00, 0x00, 0x00, 0x00,
0xc0, 0x3f, 0xc0, 0x3f, 0xc0, 0x3f, 0xc0, 0xf4, 0x04, 0x62, 0xc8, 0x00, 0x00, 0x00, 0x00, 0x00,
0x3f, 0xc0, 0x3f, 0xc0, 0x3f, 0xc0, 0x3f, 0xf4, 0x24, 0x00, 0x08, 0x00, 0x00, 0x00, 0x00, 0x00,
0x00, 0x00, 0x00, 0x00, 0x00, 0x00, 0x00, 0x13, 0x04, 0x24, 0x88, 0x00, 0x00, 0x00, 0x00, 0x00,
0xc0, 0x3f, 0xc0, 0x3f, 0xc0, 0x3f, 0xc0, 0x31, 0xfe, 0x3f, 0x90, 0x00, 0x00, 0x00, 0x00, 0x00,
0x3f, 0xc0, 0x3f, 0xc0, 0x3f, 0xc0, 0x3f, 0xf8, 0x01, 0x00, 0x20, 0x00, 0x00, 0x00, 0x00, 0x00,
0x00, 0x00, 0x00, 0x00, 0x00, 0x00, 0x00, 0x47, 0xff, 0xff, 0xc0, 0x00, 0x00, 0x00, 0x00, 0x00,
0xc0, 0x3f, 0xc0, 0x3f, 0xc0, 0x3f, 0xc0, 0x4d, 0x20, 0x94, 0x80, 0x00, 0x00, 0x00, 0x00, 0x00,
0x3f, 0xc0, 0x3f, 0xc0, 0x3f, 0xc0, 0x3f, 0xf9, 0xc0, 0x73, 0x00, 0x00, 0x00, 0x00, 0x00, 0x00,
0x00, 0x00, 0x00, 0x00, 0x00, 0x00, 0x00, 0x00, 0x00, 0x00, 0x00, 0x00, 0x00, 0x00, 0x00, 0x00,
0x00, 0x00, 0x00, 0x00, 0x00, 0x00, 0x00, 0x00, 0x00, 0x00, 0x00, 0x00, 0x00, 0x00, 0x00, 0x00,
0x00, 0x00, 0x00, 0x00, 0x00, 0x00, 0x00, 0x00, 0x00, 0x00, 0x00, 0x00, 0x00, 0x00, 0x00, 0x00,
0x00, 0x00, 0x00, 0x00, 0x00, 0x00, 0x00, 0x00, 0x00, 0x00, 0x00, 0x00, 0x00, 0x00, 0x00, 0x00,
0x00, 0x00, 0x00, 0x00, 0x00, 0x00, 0x00, 0x00, 0x00, 0x00, 0x00, 0x00, 0x00, 0x00, 0x00, 0x00,
0x00, 0x00, 0x00, 0x00, 0x00, 0x00, 0x00, 0x00, 0x00, 0x00, 0x00, 0x00, 0x00, 0x00, 0x00, 0x00
},{
0x00, 0x00, 0x00, 0x00, 0x00, 0x00, 0x00, 0x00, 0x00, 0x00, 0x00, 0x00, 0x00, 0x00, 0x00, 0x00,
0x00, 0x00, 0x00, 0x00, 0x00, 0x00, 0x00, 0x00, 0x00, 0x00, 0x00, 0x00, 0x00, 0x00, 0x00, 0x00,
0x00, 0x00, 0x00, 0x00, 0x00, 0x00, 0x00, 0x00, 0x00, 0x00, 0x00, 0x00, 0x00, 0x00, 0x00, 0x00,
0x00, 0x00, 0x00, 0x00, 0x00, 0x00, 0x00, 0x00, 0x00, 0x00, 0x00, 0x00, 0x00, 0x00, 0x00, 0x00,
0x00, 0x00, 0x00, 0x00, 0x00, 0x00, 0x00, 0x00, 0x00, 0x00, 0x00, 0x00, 0x00, 0x00, 0x00, 0x00,
0x00, 0x00, 0x00, 0x00, 0x00, 0x00, 0x00, 0x00, 0x00, 0x00, 0x00, 0x00, 0x00, 0x00, 0x00, 0x00,
0x80, 0x7f, 0x80, 0x7f, 0x80, 0x7f, 0x80, 0x7f, 0xff, 0xfc, 0x00, 0x00, 0x00, 0x00, 0x00, 0x00,
0x7f, 0x80, 0x7f, 0x80, 0x7f, 0x80, 0x7f, 0x88, 0x00, 0x02, 0x00, 0x00, 0x00, 0x00, 0x00, 0x00,
0x00, 0x00, 0x00, 0x00, 0x00, 0x00, 0x00, 0x11, 0xff, 0xf1, 0x00, 0x00, 0x00, 0x00, 0x00, 0x00,
0x80, 0x7f, 0x80, 0x7f, 0x80, 0x7f, 0x80, 0x72, 0x09, 0x09, 0x00, 0x00, 0x00, 0x00, 0x00, 0x00,
0x7f, 0x80, 0x7f, 0x80, 0x7f, 0x80, 0x7f, 0x95, 0x00, 0x05, 0x00, 0x00, 0x00, 0x00, 0x00, 0x00,
0x00, 0x00, 0x00, 0x00, 0x00, 0x00, 0x00, 0x14, 0x00, 0xd5, 0x30, 0x00, 0x00, 0x00, 0x00, 0x00,
0x80, 0x7f, 0x80, 0x7f, 0x80, 0x7f, 0x80, 0x74, 0x01, 0x25, 0x48, 0x00, 0x00, 0x00, 0x00, 0x00,
0x7f, 0x80, 0x7f, 0x80, 0x7f, 0x80, 0x7f, 0x94, 0x11, 0x15, 0x88, 0x00, 0x00, 0x00, 0x00, 0x00,
0x00, 0x00, 0x00, 0x00, 0x00, 0x00, 0x03, 0x14, 0x01, 0x0f, 0x08, 0x00, 0x00, 0x00, 0x00, 0x00,
0x80, 0x7f, 0x80, 0x7f, 0x80, 0x7f, 0x84, 0xf4, 0x81, 0x00, 0x08, 0x00, 0x00, 0x00, 0x00, 0x00,
0x7f, 0x80, 0x7f, 0x80, 0x7f, 0x80, 0x7c, 0xf4, 0x0a, 0x00, 0x04, 0x00, 0x00, 0x00, 0x00, 0x00,
0x00, 0x00, 0x00, 0x00, 0x00, 0x00, 0x02, 0x16, 0x02, 0x10, 0x24, 0x00, 0x00, 0x00, 0x00, 0x00,
0x80, 0x7f, 0x80, 0x7f, 0x80, 0x7f, 0x81, 0x94, 0x02, 0x31, 0x64, 0x00, 0x00, 0x00, 0x00, 0x00,
0x7f, 0x80, 0x7f, 0x80, 0x7f, 0x80, 0x7f, 0xf4, 0x22, 0x00, 0x04, 0x00, 0x00, 0x00, 0x00, 0x00,
0x00, 0x00, 0x00, 0x00, 0x00, 0x00, 0x00, 0x13, 0x02, 0x12, 0x44, 0x00, 0x00, 0x00, 0x00, 0x00,
0x80, 0x7f, 0x80, 0x7f, 0x80, 0x7f, 0x80, 0x71, 0xff, 0x1f, 0xc8, 0x00, 0x00, 0x00, 0x00, 0x00,
0x7f, 0x80, 0x7f, 0x80, 0x7f, 0x80, 0x7f, 0x98, 0x00, 0x80, 0x10, 0x00, 0x00, 0x00, 0x00, 0x00,
0x00, 0x00, 0x00, 0x00, 0x00, 0x00, 0x00, 0x27, 0xff, 0xff, 0xe0, 0x00, 0x00, 0x00, 0x00, 0x00,
0x80, 0x7f, 0x80, 0x7f, 0x80, 0x7f, 0x80, 0x65, 0x20, 0x4a, 0x40, 0x00, 0x00, 0x00, 0x00, 0x00,
0x7f, 0x80, 0x7f, 0x80, 0x7f, 0x80, 0x7f, 0xb8, 0xe0, 0x39, 0xc0, 0x00, 0x00, 0x00, 0x00, 0x00,
0x00, 0x00, 0x00, 0x00, 0x00, 0x00, 0x00, 0x00, 0x00, 0x00, 0x00, 0x00, 0x00, 0x00, 0x00, 0x00,
0x00, 0x00, 0x00, 0x00, 0x00, 0x00, 0x00, 0x00, 0x00, 0x00, 0x00, 0x00, 0x00, 0x00, 0x00, 0x00,
0x00, 0x00, 0x00, 0x00, 0x00, 0x00, 0x00, 0x00, 0x00, 0x00, 0x00, 0x00, 0x00, 0x00, 0x00, 0x00,
0x00, 0x00, 0x00, 0x00, 0x00, 0x00, 0x00, 0x00, 0x00, 0x00, 0x00, 0x00, 0x00, 0x00, 0x00, 0x00,
0x00, 0x00, 0x00, 0x00, 0x00, 0x00, 0x00, 0x00, 0x00, 0x00, 0x00, 0x00, 0x00, 0x00, 0x00, 0x00,
0x00, 0x00, 0x00, 0x00, 0x00, 0x00, 0x00, 0x00, 0x00, 0x00, 0x00, 0x00, 0x00, 0x00, 0x00, 0x00
},{
0x00, 0x00, 0x00, 0x00, 0x00, 0x00, 0x00, 0x00, 0x00, 0x00, 0x00, 0x00, 0x00, 0x00, 0x00, 0x00,
0x00, 0x00, 0x00, 0x00, 0x00, 0x00, 0x00, 0x00, 0x00, 0x00, 0x00, 0x00, 0x00, 0x00, 0x00, 0x00,
0x00, 0x00, 0x00, 0x00, 0x00, 0x00, 0x00, 0x00, 0x00, 0x00, 0x00, 0x00, 0x00, 0x00, 0x00, 0x00,
0x00, 0x00, 0x00, 0x00, 0x00, 0x00, 0x00, 0x00, 0x00, 0x00, 0x00, 0x00, 0x00, 0x00, 0x00, 0x00,
0x00, 0x00, 0x00, 0x00, 0x00, 0x00, 0x00, 0x00, 0x00, 0x00, 0x00, 0x00, 0x00, 0x00, 0x00, 0x00,
0x00, 0x00, 0x00, 0x00, 0x00, 0x00, 0x00, 0x00, 0x00, 0x00, 0x00, 0x00, 0x00, 0x00, 0x00, 0x00,
0x3f, 0xc0, 0x3f, 0xc0, 0x3f, 0xc0, 0x3f, 0xc0, 0x00, 0x00, 0x00, 0x00, 0x00, 0x00, 0x00, 0x00,
0xc0, 0x3f, 0xc0, 0x3f, 0xc0, 0x3f, 0xc0, 0x3f, 0xff, 0xfc, 0x00, 0x00, 0x00, 0x00, 0x00, 0x00,
0x00, 0x00, 0x00, 0x00, 0x00, 0x00, 0x00, 0x08, 0x00, 0x02, 0x00, 0x00, 0x00, 0x00, 0x00, 0x00,
0x3f, 0xc0, 0x3f, 0xc0, 0x3f, 0xc0, 0x3f, 0xd1, 0xff, 0xf1, 0x00, 0x00, 0x00, 0x00, 0x00, 0x00,
0xc0, 0x3f, 0xc0, 0x3f, 0xc0, 0x3f, 0xc0, 0x32, 0x09, 0x09, 0x00, 0x00, 0x00, 0x00, 0x00, 0x00,
0x00, 0x00, 0x00, 0x00, 0x00, 0x00, 0x00, 0x15, 0x00, 0x05, 0x00, 0x00, 0x00, 0x00, 0x00, 0x00,
0x3f, 0xc0, 0x3f, 0xc0, 0x3f, 0xc0, 0x3f, 0xd4, 0x00, 0xd5, 0x30, 0x00, 0x00, 0x00, 0x00, 0x00,
0xc0, 0x3f, 0xc0, 0x3f, 0xc0, 0x3f, 0xc0, 0x34, 0x01, 0x25, 0x48, 0x00, 0x00, 0x00, 0x00, 0x00,
0x00, 0x00, 0x00, 0x00, 0x00, 0x00, 0x00, 0x14, 0x11, 0x15, 0x88, 0x00, 0x00, 0x00, 0x00, 0x00,
0x3f, 0xc0, 0x3f, 0xc0, 0x3f, 0xc0, 0x3f, 0xd4, 0x01, 0x0f, 0x08, 0x00, 0x00, 0x00, 0x00, 0x00,
0xc0, 0x3f, 0xc0, 0x3f, 0xc0, 0x3f, 0xc0, 0x34, 0x81, 0x00, 0x08, 0x00, 0x00, 0x00, 0x00, 0x00,
0x00, 0x00, 0x00, 0x00, 0x00, 0x00, 0x00, 0x34, 0x0a, 0x00, 0x04, 0x00, 0x00, 0x00, 0x00, 0x00,
0x3f, 0xc0, 0x3f, 0xc0, 0x3f, 0xc0, 0x3f, 0xf6, 0x02, 0x10, 0x24, 0x00, 0x00, 0x00, 0x00, 0x00,
0xc0, 0x3f, 0xc0, 0x3f, 0xc0, 0x3f, 0xc6, 0x14, 0x02, 0x31, 0x64, 0x00, 0x00, 0x00, 0x00, 0x00,
0x00, 0x00, 0x00, 0x00, 0x00, 0x00, 0x04, 0x74, 0x22, 0x00, 0x04, 0x00, 0x00, 0x00, 0x00, 0x00,
0x3f, 0xc0, 0x3f, 0xc0, 0x3f, 0xc0, 0x3f, 0xd3, 0x02, 0x12, 0x44, 0x00, 0x00, 0x00, 0x00, 0x00,
0xc0, 0x3f, 0xc0, 0x3f, 0xc0, 0x3f, 0xc0, 0x31, 0xff, 0x1f, 0xc8, 0x00, 0x00, 0x00, 0x00, 0x00,
0x00, 0x00, 0x00, 0x00, 0x00, 0x00, 0x00, 0x18, 0x00, 0x80, 0x10, 0x00, 0x00, 0x00, 0x00, 0x00,
0x3f, 0xc0, 0x3f, 0xc0, 0x3f, 0xc0, 0x3f, 0xd7, 0xff, 0xff, 0xe0, 0x00, 0x00, 0x00, 0x00, 0x00,
0xc0, 0x3f, 0xc0, 0x3f, 0xc0, 0x3f, 0xc0, 0x32, 0x90, 0x25, 0x20, 0x00, 0x00, 0x00, 0x00, 0x00,
0x00, 0x00, 0x00, 0x00, 0x00, 0x00, 0x00, 0x1c, 0x70, 0x1c, 0xe0, 0x00, 0x00, 0x00, 0x00, 0x00,
0x00, 0x00, 0x00, 0x00, 0x00, 0x00, 0x00, 0x00, 0x00, 0x00, 0x00, 0x00, 0x00, 0x00, 0x00, 0x00,
0x00, 0x00, 0x00, 0x00, 0x00, 0x00, 0x00, 0x00, 0x00, 0x00, 0x00, 0x00, 0x00, 0x00, 0x00, 0x00,
0x00, 0x00, 0x00, 0x00, 0x00, 0x00, 0x00, 0x00, 0x00, 0x00, 0x00, 0x00, 0x00, 0x00, 0x00, 0x00,
0x00, 0x00, 0x00, 0x00, 0x00, 0x00, 0x00, 0x00, 0x00, 0x00, 0x00, 0x00, 0x00, 0x00, 0x00, 0x00,
0x00, 0x00, 0x00, 0x00, 0x00, 0x00, 0x00, 0x00, 0x00, 0x00, 0x00, 0x00, 0x00, 0x00, 0x00, 0x00
},{
0x00, 0x00, 0x00, 0x00, 0x00, 0x00, 0x00, 0x00, 0x00, 0x00, 0x00, 0x00, 0x00, 0x00, 0x00, 0x00,
0x00, 0x00, 0x00, 0x00, 0x00, 0x00, 0x00, 0x00, 0x00, 0x00, 0x00, 0x00, 0x00, 0x00, 0x00, 0x00,
0x00, 0x00, 0x00, 0x00, 0x00, 0x00, 0x00, 0x00, 0x00, 0x00, 0x00, 0x00, 0x00, 0x00, 0x00, 0x00,
0x00, 0x00, 0x00, 0x00, 0x00, 0x00, 0x00, 0x00, 0x00, 0x00, 0x00, 0x00, 0x00, 0x00, 0x00, 0x00,
0x00, 0x00, 0x00, 0x00, 0x00, 0x00, 0x00, 0x00, 0x00, 0x00, 0x00, 0x00, 0x00, 0x00, 0x00, 0x00,
0x00, 0x00, 0x00, 0x00, 0x00, 0x00, 0x00, 0x00, 0x00, 0x00, 0x00, 0x00, 0x00, 0x00, 0x00, 0x00,
0x7f, 0x80, 0x7f, 0x80, 0x7f, 0x80, 0x7f, 0x80, 0x00, 0x00, 0x00, 0x00, 0x00, 0x00, 0x00, 0x00,
0x80, 0x7f, 0x80, 0x7f, 0x80, 0x7f, 0x80, 0x7f, 0xff, 0xfc, 0x00, 0x00, 0x00, 0x00, 0x00, 0x00,
0x00, 0x00, 0x00, 0x00, 0x00, 0x00, 0x00, 0x08, 0x00, 0x02, 0x00, 0x00, 0x00, 0x00, 0x00, 0x00,
0x7f, 0x80, 0x7f, 0x80, 0x7f, 0x80, 0x7f, 0x91, 0xff, 0xf1, 0x00, 0x00, 0x00, 0x00, 0x00, 0x00,
0x80, 0x7f, 0x80, 0x7f, 0x80, 0x7f, 0x80, 0x72, 0x09, 0x09, 0x00, 0x00, 0x00, 0x00, 0x00, 0x00,
0x00, 0x00, 0x00, 0x00, 0x00, 0x00, 0x00, 0x15, 0x00, 0x05, 0x00, 0x00, 0x00, 0x00, 0x00, 0x00,
0x7f, 0x80, 0x7f, 0x80, 0x7f, 0x80, 0x7f, 0x94, 0x00, 0xd5, 0x30, 0x00, 0x00, 0x00, 0x00, 0x00,
0x80, 0x7f, 0x80, 0x7f, 0x80, 0x7f, 0x80, 0x74, 0x01, 0x25, 0x48, 0x00, 0x00, 0x00, 0x00, 0x00,
0x00, 0x00, 0x00, 0x00, 0x00, 0x00, 0x00, 0x14, 0x11, 0x15, 0x88, 0x00, 0x00, 0x00, 0x00, 0x00,
0x7f, 0x80, 0x7f, 0x80, 0x7f, 0x80, 0x7f, 0x94, 0x01, 0x0f, 0x08, 0x00, 0x00, 0x00, 0x00, 0x00,
0x80, 0x7f, 0x80, 0x7f, 0x80, 0x7f, 0x80, 0x74, 0x81, 0x00, 0x08, 0x00, 0x00, 0x00, 0x00, 0x00,
0x00, 0x00, 0x00, 0x00, 0x00, 0x00, 0x00, 0x74, 0x0a, 0x00, 0x04, 0x00, 0x00, 0x00, 0x00, 0x00,
0x7f, 0x80, 0x7f, 0x80, 0x7f, 0x80, 0x7f, 0x96, 0x02, 0x10, 0x24, 0x00, 0x00, 0x00, 0x00, 0x00,
0x80, 0x7f, 0x80, 0x7f, 0x80, 0x7f, 0x82, 0x14, 0x02, 0x31, 0x64, 0x00, 0x00, 0x00, 0x00, 0x00,
0x00, 0x00, 0x00, 0x00, 0x00, 0x00, 0x04, 0xf4, 0x22, 0x00, 0x04, 0x00, 0x00, 0x00, 0x00, 0x00,
0x7f, 0x80, 0x7f, 0x80, 0x7f, 0x80, 0x7c, 0x93, 0x02, 0x12, 0x44, 0x00, 0x00, 0x00, 0x00, 0x00,
0x80, 0x7f, 0x80, 0x7f, 0x80, 0x7f, 0x83, 0x71, 0xff, 0x1f, 0xc8, 0x00, 0x00, 0x00, 0x00, 0x00,
0x00, 0x00, 0x00, 0x00, 0x00, 0x00, 0x00, 0x18, 0x00, 0x80, 0x10, 0x00, 0x00, 0x00, 0x00, 0x00,
0x7f, 0x80, 0x7f, 0x80, 0x7f, 0x80, 0x7f, 0xa7, 0xff, 0xff, 0xe0, 0x00, 0x00, 0x00, 0x00, 0x00,
0x80, 0x7f, 0x80, 0x7f, 0x80, 0x7f, 0x80, 0x65, 0x20, 0x4a, 0x40, 0x00, 0x00, 0x00, 0x00, 0x00,
0x00, 0x00, 0x00, 0x00, 0x00, 0x00, 0x00, 0x38, 0xe0, 0x39, 0xc0, 0x00, 0x00, 0x00, 0x00, 0x00,
0x00, 0x00, 0x00, 0x00, 0x00, 0x00, 0x00, 0x00, 0x00, 0x00, 0x00, 0x00, 0x00, 0x00, 0x00, 0x00,
0x00, 0x00, 0x00, 0x00, 0x00, 0x00, 0x00, 0x00, 0x00, 0x00, 0x00, 0x00, 0x00, 0x00, 0x00, 0x00,
0x00, 0x00, 0x00, 0x00, 0x00, 0x00, 0x00, 0x00, 0x00, 0x00, 0x00, 0x00, 0x00, 0x00, 0x00, 0x00,
0x00, 0x00, 0x00, 0x00, 0x00, 0x00, 0x00, 0x00, 0x00, 0x00, 0x00, 0x00, 0x00, 0x00, 0x00, 0x00,
0x00, 0x00, 0x00, 0x00, 0x00, 0x00, 0x00, 0x00, 0x00, 0x00, 0x00, 0x00, 0x00, 0x00, 0x00, 0x00
},{
0x00, 0x00, 0x00, 0x00, 0x00, 0x00, 0x00, 0x00, 0x00, 0x00, 0x00, 0x00, 0x00, 0x00, 0x00, 0x00,
0x00, 0x00, 0x00, 0x00, 0x00, 0x00, 0x00, 0x00, 0x00, 0x00, 0x00, 0x00, 0x00, 0x00, 0x00, 0x00,
0x00, 0x00, 0x00, 0x00, 0x00, 0x00, 0x00, 0x00, 0x00, 0x00, 0x00, 0x00, 0x00, 0x00, 0x00, 0x00,
0x00, 0x00, 0x00, 0x00, 0x00, 0x00, 0x00, 0x00, 0x00, 0x00, 0x00, 0x00, 0x00, 0x00, 0x00, 0x00,
0x00, 0x00, 0x00, 0x00, 0x00, 0x00, 0x00, 0x00, 0x00, 0x00, 0x00, 0x00, 0x00, 0x00, 0x00, 0x00,
0x00, 0x00, 0x00, 0x00, 0x00, 0x00, 0x00, 0x00, 0x00, 0x00, 0x00, 0x00, 0x00, 0x00, 0x00, 0x00,
0xc0, 0x3f, 0xc0, 0x3f, 0xc0, 0x3f, 0xc0, 0x3f, 0xc0, 0x00, 0x00, 0x00, 0x00, 0x00, 0x00, 0x00,
0x3f, 0xc0, 0x3f, 0xc0, 0x3f, 0xc0, 0x3f, 0xc7, 0xff, 0xfc, 0x00, 0x00, 0x00, 0x00, 0x00, 0x00,
0x00, 0x00, 0x00, 0x00, 0x00, 0x00, 0x00, 0x08, 0x00, 0x02, 0x00, 0x00, 0x00, 0x00, 0x00, 0x00,
0xc0, 0x3f, 0xc0, 0x3f, 0xc0, 0x3f, 0xc0, 0x31, 0xff, 0xf1, 0x00, 0x00, 0x00, 0x00, 0x00, 0x00,
0x3f, 0xc0, 0x3f, 0xc0, 0x3f, 0xc0, 0x3f, 0xd2, 0x09, 0x09, 0x00, 0x00, 0x00, 0x00, 0x00, 0x00,
0x00, 0x00, 0x00, 0x00, 0x00, 0x00, 0x00, 0x15, 0x00, 0x05, 0x00, 0x00, 0x00, 0x00, 0x00, 0x00,
0xc0, 0x3f, 0xc0, 0x3f, 0xc0, 0x3f, 0xc0, 0x34, 0x01, 0x95, 0x60, 0x00, 0x00, 0x00, 0x00, 0x00,
0x3f, 0xc0, 0x3f, 0xc0, 0x3f, 0xc0, 0x3f, 0xd4, 0x02, 0x45, 0x90, 0x00, 0x00, 0x00, 0x00, 0x00,
0x00, 0x00, 0x00, 0x00, 0x00, 0x00, 0x00, 0x14, 0x12, 0x25, 0x10, 0x00, 0x00, 0x00, 0x00, 0x00,
0xc0, 0x3f, 0xc0, 0x3f, 0xc0, 0x3f, 0xc7, 0xb4, 0x02, 0x1e, 0x10, 0x00, 0x00, 0x00, 0x00, 0x00,
0x3f, 0xc0, 0x3f, 0xc0, 0x3f, 0xc0, 0x38, 0xf4, 0x82, 0x00, 0x10, 0x00, 0x00, 0x00, 0x00, 0x00,
0x00, 0x00, 0x00, 0x00, 0x00, 0x00, 0x0c, 0x34, 0x0c, 0x00, 0x08, 0x00, 0x00, 0x00, 0x00, 0x00,
0xc0, 0x3f, 0xc0, 0x3f, 0xc0, 0x3f, 0xc3, 0xd6, 0x04, 0x20, 0x48, 0x00, 0x00, 0x00, 0x00, 0x00,
0x3f, 0xc0, 0x3f, 0xc0, 0x3f, 0xc0, 0x3f, 0xf4, 0x04, 0x62, 0xc8, 0x00, 0x00, 0x00, 0x00, 0x00,
0x00, 0x00, 0x00, 0x00, 0x00, 0x00, 0x00, 0x14, 0x24, 0x00, 0x08, 0x00, 0x00, 0x00, 0x00, 0x00,
0xc0, 0x3f, 0xc0, 0x3f, 0xc0, 0x3f, 0xc0, 0x33, 0x04, 0x24, 0x88, 0x00, 0x00, 0x00, 0x00, 0x00,
0x3f, 0xc0, 0x3f, 0xc0, 0x3f, 0xc0, 0x3f, 0xf1, 0xfe, 0x3f, 0x90, 0x00, 0x00, 0x00, 0x00, 0x00,
0x00, 0x00, 0x00, 0x00, 0x00, 0x00, 0x00, 0x78, 0x01, 0x00, 0x20, 0x00, 0x00, 0x00, 0x00, 0x00,
0xc0, 0x3f, 0xc0, 0x3f, 0xc0, 0x3f, 0xc0, 0x8f, 0xff, 0xff, 0xc0, 0x00, 0x00, 0x00, 0x00, 0x00,
0x3f, 0xc0, 0x3f, 0xc0, 0x3f, 0xc0, 0x3f, 0x94, 0x81, 0x29, 0x00, 0x00, 0x00, 0x00, 0x00, 0x00,
0x00, 0x00, 0x00, 0x00, 0x00, 0x00, 0x00, 0xe3, 0x80, 0xe7, 0x00, 0x00, 0x00, 0x00, 0x00, 0x00,
0x00, 0x00, 0x00, 0x00, 0x00, 0x00, 0x00, 0x00, 0x00, 0x00, 0x00, 0x00, 0x00, 0x00, 0x00, 0x00,
0x00, 0x00, 0x00, 0x00, 0x00, 0x00, 0x00, 0x00, 0x00, 0x00, 0x00, 0x00, 0x00, 0x00, 0x00, 0x00,
0x00, 0x00, 0x00, 0x00, 0x00, 0x00, 0x00, 0x00, 0x00, 0x00, 0x00, 0x00, 0x00, 0x00, 0x00, 0x00,
0x00, 0x00, 0x00, 0x00, 0x00, 0x00, 0x00, 0x00, 0x00, 0x00, 0x00, 0x00, 0x00, 0x00, 0x00, 0x00,
0x00, 0x00, 0x00, 0x00, 0x00, 0x00, 0x00, 0x00, 0x00, 0x00, 0x00, 0x00, 0x00, 0x00, 0x00, 0x00
},{
0x00, 0x00, 0x00, 0x00, 0x00, 0x00, 0x00, 0x00, 0x00, 0x00, 0x00, 0x00, 0x00, 0x00, 0x00, 0x00,
0x00, 0x00, 0x00, 0x00, 0x00, 0x00, 0x00, 0x00, 0x00, 0x00, 0x00, 0x00, 0x00, 0x00, 0x00, 0x00,
0x00, 0x00, 0x00, 0x00, 0x00, 0x00, 0x00, 0x00, 0x00, 0x00, 0x00, 0x00, 0x00, 0x00, 0x00, 0x00,
0x00, 0x00, 0x00, 0x00, 0x00, 0x00, 0x00, 0x00, 0x00, 0x00, 0x00, 0x00, 0x00, 0x00, 0x00, 0x00,
0x00, 0x00, 0x00, 0x00, 0x00, 0x00, 0x00, 0x00, 0x00, 0x00, 0x00, 0x00, 0x00, 0x00, 0x00, 0x00,
0x00, 0x00, 0x00, 0x00, 0x00, 0x00, 0x00, 0x00, 0x00, 0x00, 0x00, 0x00, 0x00, 0x00, 0x00, 0x00,
0xc0, 0x3f, 0xc0, 0x3f, 0xc0, 0x3f, 0xc0, 0x3f, 0xc0, 0x00, 0x00, 0x00, 0x00, 0x00, 0x00, 0x00,
0x3f, 0xc0, 0x3f, 0xc0, 0x3f, 0xc0, 0x3f, 0xc7, 0xff, 0xfc, 0x00, 0x00, 0x00, 0x00, 0x00, 0x00,
0x00, 0x00, 0x00, 0x00, 0x00, 0x00, 0x00, 0x08, 0x00, 0x02, 0x00, 0x00, 0x00, 0x00, 0x00, 0x00,
0xc0, 0x3f, 0xc0, 0x3f, 0xc0, 0x3f, 0xc0, 0x31, 0xff, 0xf1, 0x00, 0x00, 0x00, 0x00, 0x00, 0x00,
0x3f, 0xc0, 0x3f, 0xc0, 0x3f, 0xc0, 0x3f, 0xd2, 0x09, 0x09, 0x00, 0x00, 0x00, 0x00, 0x00, 0x00,
0x00, 0x00, 0x00, 0x00, 0x00, 0x00, 0x00, 0x15, 0x00, 0x05, 0x00, 0x00, 0x00, 0x00, 0x00, 0x00,
0xc0, 0x3f, 0xc0, 0x3f, 0xc0, 0x3f, 0xc0, 0x34, 0x01, 0x95, 0x60, 0x00, 0x00, 0x00, 0x00, 0x00,
0x3f, 0xc0, 0x3f, 0xc0, 0x3f, 0xc0, 0x3f, 0xd4, 0x02, 0x45, 0x90, 0x00, 0x00, 0x00, 0x00, 0x00,
0x00, 0x00, 0x00, 0x00, 0x00, 0x00, 0x00, 0x14, 0x12, 0x25, 0x10, 0x00, 0x00, 0x00, 0x00, 0x00,
0xc0, 0x3f, 0xc0, 0x3f, 0xc0, 0x3f, 0xc7, 0xb4, 0x02, 0x1e, 0x10, 0x00, 0x00, 0x00, 0x00, 0x00,
0x3f, 0xc0, 0x3f, 0xc0, 0x3f, 0xc0, 0x38, 0xf4, 0x82, 0x00, 0x10, 0x00, 0x00, 0x00, 0x00, 0x00,
0x00, 0x00, 0x00, 0x00, 0x00, 0x00, 0x0c, 0x34, 0x0c, 0x00, 0x08, 0x00, 0x00, 0x00, 0x00, 0x00,
0xc0, 0x3f, 0xc0, 0x3f, 0xc0, 0x3f, 0xc3, 0xd6, 0x04, 0x20, 0x48, 0x00, 0x00, 0x00, 0x00, 0x00,
0x3f, 0xc0, 0x3f, 0xc0, 0x3f, 0xc0, 0x3f, 0xf4, 0x04, 0x62, 0xc8, 0x00, 0x00, 0x00, 0x00, 0x00,
0x00, 0x00, 0x00, 0x00, 0x00, 0x00, 0x00, 0x14, 0x24, 0x00, 0x08, 0x00, 0x00, 0x00, 0x00, 0x00,
0xc0, 0x3f, 0xc0, 0x3f, 0xc0, 0x3f, 0xc0, 0x33, 0x04, 0x24, 0x88, 0x00, 0x00, 0x00, 0x00, 0x00,
0x3f, 0xc0, 0x3f, 0xc0, 0x3f, 0xc0, 0x3f, 0xf1, 0xfe, 0x3f, 0x90, 0x00, 0x00, 0x00, 0x00, 0x00,
0x00, 0x00, 0x00, 0x00, 0x00, 0x00, 0x00, 0x78, 0x01, 0x00, 0x20, 0x00, 0x00, 0x00, 0x00, 0x00,
0xc0, 0x3f, 0xc0, 0x3f, 0xc0, 0x3f, 0xc0, 0x8f, 0xff, 0xff, 0xc0, 0x00, 0x00, 0x00, 0x00, 0x00,
0x3f, 0xc0, 0x3f, 0xc0, 0x3f, 0xc0, 0x3f, 0x94, 0x81, 0x29, 0x00, 0x00, 0x00, 0x00, 0x00, 0x00,
0x00, 0x00, 0x00, 0x00, 0x00, 0x00, 0x00, 0xe3, 0x80, 0xe7, 0x00, 0x00, 0x00, 0x00, 0x00, 0x00,
0x00, 0x00, 0x00, 0x00, 0x00, 0x00, 0x00, 0x00, 0x00, 0x00, 0x00, 0x00, 0x00, 0x00, 0x00, 0x00,
0x00, 0x00, 0x00, 0x00, 0x00, 0x00, 0x00, 0x00, 0x00, 0x00, 0x00, 0x00, 0x00, 0x00, 0x00, 0x00,
0x00, 0x00, 0x00, 0x00, 0x00, 0x00, 0x00, 0x00, 0x00, 0x00, 0x00, 0x00, 0x00, 0x00, 0x00, 0x00,
0x00, 0x00, 0x00, 0x00, 0x00, 0x00, 0x00, 0x00, 0x00, 0x00, 0x00, 0x00, 0x00, 0x00, 0x00, 0x00,
0x00, 0x00, 0x00, 0x00, 0x00, 0x00, 0x00, 0x00, 0x00, 0x00, 0x00, 0x00, 0x00, 0x00, 0x00, 0x00
}};
/* USER CODE END PV */

void SystemClock_Config(void);
static void MX_GPIO_Init(void);
static void MX_I2C1_Init(void);
static void MX_SPI1_Init(void);
static void MX_USB_PCD_Init(void);
static void MX_UART4_Init(void);
static void MX_I2C2_Init(void);

/* USER CODE BEGIN 0 */
#define LCD_ADDR (0x27 << 1)

#define PIN_RS    (1 << 0)
#define PIN_EN    (1 << 2)
#define BACKLIGHT (1 << 3)

#define LCD_DELAY_MS 5

void I2C_Scan() {
    char info[] = "Scanning I2C bus...\r\n";
    HAL_UART_Transmit(&huart4, (uint8_t*)info, strlen(info), HAL_MAX_DELAY);

    HAL_StatusTypeDef res;
    for(uint16_t i = 0; i < 128; i++) {
        res = HAL_I2C_IsDeviceReady(&hi2c2, i << 1, 1, 10);
        if(res == HAL_OK) {
            char msg[64];
            snprintf(msg, sizeof(msg), "0x%02X", i);
            HAL_UART_Transmit(&huart4, (uint8_t*)msg, strlen(msg), HAL_MAX_DELAY);
        } else {
            HAL_UART_Transmit(&huart4, (uint8_t*)".", 1, HAL_MAX_DELAY);
        }
    }

    HAL_UART_Transmit(&huart4, (uint8_t*)"\r\n", 2, HAL_MAX_DELAY);
}

HAL_StatusTypeDef LCD_SendInternal(uint8_t lcd_addr, uint8_t data, uint8_t flags) {
    HAL_StatusTypeDef res;
    for(;;) {
        res = HAL_I2C_IsDeviceReady(&hi2c2, lcd_addr, 1, HAL_MAX_DELAY);
        if(res == HAL_OK)
            break;
    }

    uint8_t up = data & 0xF0;
    uint8_t lo = (data << 4) & 0xF0;

    uint8_t data_arr[4];
    data_arr[0] = up|flags|BACKLIGHT|PIN_EN;
    data_arr[1] = up|flags|BACKLIGHT;
    data_arr[2] = lo|flags|BACKLIGHT|PIN_EN;
    data_arr[3] = lo|flags|BACKLIGHT;

    res = HAL_I2C_Master_Transmit(&hi2c2, lcd_addr, data_arr, sizeof(data_arr), HAL_MAX_DELAY);
    HAL_Delay(LCD_DELAY_MS);
    return res;
}

void LCD_SendCommand(uint8_t lcd_addr, uint8_t cmd) {
    LCD_SendInternal(lcd_addr, cmd, 0);
}

void LCD_SendData(uint8_t lcd_addr, uint8_t data) {
    LCD_SendInternal(lcd_addr, data, PIN_RS);
}
void LCD_Init(uint8_t lcd_addr) {
    // 4-bit mode, 2 lines, 5x7 format
    LCD_SendCommand(lcd_addr, 0b00110000);
    // display & cursor home (keep this!)
    LCD_SendCommand(lcd_addr, 0b00000010);
    // display on, right shift, underline off, blink off
    LCD_SendCommand(lcd_addr, 0b00001100);
    // clear display (optional here)
    //LCD_SendCommand(lcd_addr, 0b00000001);
}

void LCD_SendString(uint8_t lcd_addr, char *str) {
    while(*str) {
        LCD_SendData(lcd_addr, (uint8_t)(*str));
        str++;
    }
}

void init() {
    I2C_Scan();
    LCD_Init(LCD_ADDR);

    // set address to 0x00
    LCD_SendCommand(LCD_ADDR, 0b10000000);
    LCD_SendString(LCD_ADDR, "       My");

    // set address to 0x40
    LCD_SendCommand(LCD_ADDR, 0b11000000);
    LCD_SendString(LCD_ADDR, "      project");
}

void loop() {
    HAL_Delay(100);
}

/* USER CODE END 0 */

int main(void)
{

  /* MCU Configuration--------------------------------------------------------*/

  /* Reset of all peripherals, Initializes the Flash interface and the Systick. */
  HAL_Init();

  /* Configure the system clock */
  SystemClock_Config();

  /* Initialize all configured peripherals */
  MX_GPIO_Init();
  MX_I2C1_Init();
  MX_SPI1_Init();
  MX_USB_PCD_Init();
  MX_UART4_Init();
  MX_I2C2_Init();
  /* USER CODE BEGIN 2 */
  	  ssd1306_Init();

    ssd1306_Fill(Black);
    ssd1306_SetCursor(5, 10);
    ssd1306_WriteString("Hello world!", Font_11x18, White);
    ssd1306_UpdateScreen();
  /* USER CODE END 2 */

  /* Infinite loop */
  /* USER CODE BEGIN WHILE */
   //init();

  while (1)
  {
	  	  numFrame++;
	      if (numFrame >= 12) { // if the animation ends
	        numFrame = 0; // start again from the first frame
	      }
	      ssd1306_SetCursor(10, 30);
	      ssd1306_Fill(Black);
	      ssd1306_DrawBitmap(0, 0, nyancatframes[numFrame], 128, 32, White);
	      ssd1306_UpdateScreen();
	      HAL_Delay(10);
	      //display.clearDisplay(); // clear display buffer
	      //display.drawBitmap(0, 16, nyancatframes[numFrame], 128, 32, WHITE); // draw current frame
	      //display.display(); // refresh the display to show changes
    /* USER CODE END WHILE */

  }
}

void SystemClock_Config(void)
{
  RCC_OscInitTypeDef RCC_OscInitStruct = {0};
  RCC_ClkInitTypeDef RCC_ClkInitStruct = {0};
  RCC_PeriphCLKInitTypeDef PeriphClkInit = {0};

  /** Initializes the RCC Oscillators according to the specified parameters
  * in the RCC_OscInitTypeDef structure.
  */
  RCC_OscInitStruct.OscillatorType = RCC_OSCILLATORTYPE_HSI|RCC_OSCILLATORTYPE_HSE;
  RCC_OscInitStruct.HSEState = RCC_HSE_BYPASS;
  RCC_OscInitStruct.HSEPredivValue = RCC_HSE_PREDIV_DIV1;
  RCC_OscInitStruct.HSIState = RCC_HSI_ON;
  RCC_OscInitStruct.HSICalibrationValue = RCC_HSICALIBRATION_DEFAULT;
  RCC_OscInitStruct.PLL.PLLState = RCC_PLL_ON;
  RCC_OscInitStruct.PLL.PLLSource = RCC_PLLSOURCE_HSE;
  RCC_OscInitStruct.PLL.PLLMUL = RCC_PLL_MUL6;
  if (HAL_RCC_OscConfig(&RCC_OscInitStruct) != HAL_OK)
  {
    Error_Handler();
  }

  /** Initializes the CPU, AHB and APB buses clocks
  */
  RCC_ClkInitStruct.ClockType = RCC_CLOCKTYPE_HCLK|RCC_CLOCKTYPE_SYSCLK
                              |RCC_CLOCKTYPE_PCLK1|RCC_CLOCKTYPE_PCLK2;
  RCC_ClkInitStruct.SYSCLKSource = RCC_SYSCLKSOURCE_PLLCLK;
  RCC_ClkInitStruct.AHBCLKDivider = RCC_SYSCLK_DIV1;
  RCC_ClkInitStruct.APB1CLKDivider = RCC_HCLK_DIV2;
  RCC_ClkInitStruct.APB2CLKDivider = RCC_HCLK_DIV1;

  if (HAL_RCC_ClockConfig(&RCC_ClkInitStruct, FLASH_LATENCY_1) != HAL_OK)
  {
    Error_Handler();
  }
  PeriphClkInit.PeriphClockSelection = RCC_PERIPHCLK_USB|RCC_PERIPHCLK_UART4
                              |RCC_PERIPHCLK_I2C1|RCC_PERIPHCLK_I2C2;
  PeriphClkInit.Uart4ClockSelection = RCC_UART4CLKSOURCE_PCLK1;
  PeriphClkInit.I2c1ClockSelection = RCC_I2C1CLKSOURCE_HSI;
  PeriphClkInit.I2c2ClockSelection = RCC_I2C2CLKSOURCE_HSI;
  PeriphClkInit.USBClockSelection = RCC_USBCLKSOURCE_PLL;
  if (HAL_RCCEx_PeriphCLKConfig(&PeriphClkInit) != HAL_OK)
  {
    Error_Handler();
  }
}

static void MX_I2C1_Init(void)
{

  hi2c1.Instance = I2C1;
  hi2c1.Init.Timing = 0x00101D2D;
  hi2c1.Init.OwnAddress1 = 0;
  hi2c1.Init.AddressingMode = I2C_ADDRESSINGMODE_7BIT;
  hi2c1.Init.DualAddressMode = I2C_DUALADDRESS_DISABLE;
  hi2c1.Init.OwnAddress2 = 0;
  hi2c1.Init.OwnAddress2Masks = I2C_OA2_NOMASK;
  hi2c1.Init.GeneralCallMode = I2C_GENERALCALL_DISABLE;
  hi2c1.Init.NoStretchMode = I2C_NOSTRETCH_DISABLE;
  if (HAL_I2C_Init(&hi2c1) != HAL_OK)
  {
    Error_Handler();
  }

  /** Configure Analogue filter
  */
  if (HAL_I2CEx_ConfigAnalogFilter(&hi2c1, I2C_ANALOGFILTER_DISABLE) != HAL_OK)
  {
    Error_Handler();
  }

  /** Configure Digital filter
  */
  if (HAL_I2CEx_ConfigDigitalFilter(&hi2c1, 0) != HAL_OK)
  {
    Error_Handler();
  }

}

static void MX_I2C2_Init(void)
{

  hi2c2.Instance = I2C2;
  hi2c2.Init.Timing = 0x2000090E;
  hi2c2.Init.OwnAddress1 = 0;
  hi2c2.Init.AddressingMode = I2C_ADDRESSINGMODE_7BIT;
  hi2c2.Init.DualAddressMode = I2C_DUALADDRESS_DISABLE;
  hi2c2.Init.OwnAddress2 = 0;
  hi2c2.Init.OwnAddress2Masks = I2C_OA2_NOMASK;
  hi2c2.Init.GeneralCallMode = I2C_GENERALCALL_DISABLE;
  hi2c2.Init.NoStretchMode = I2C_NOSTRETCH_DISABLE;
  if (HAL_I2C_Init(&hi2c2) != HAL_OK)
  {
    Error_Handler();
  }

  /** Configure Analogue filter
  */
  if (HAL_I2CEx_ConfigAnalogFilter(&hi2c2, I2C_ANALOGFILTER_ENABLE) != HAL_OK)
  {
    Error_Handler();
  }

  /** Configure Digital filter
  */
  if (HAL_I2CEx_ConfigDigitalFilter(&hi2c2, 0) != HAL_OK)
  {
    Error_Handler();
  }

}

static void MX_SPI1_Init(void)
{

  /* SPI1 parameter configuration*/
  hspi1.Instance = SPI1;
  hspi1.Init.Mode = SPI_MODE_MASTER;
  hspi1.Init.Direction = SPI_DIRECTION_2LINES;
  hspi1.Init.DataSize = SPI_DATASIZE_4BIT;
  hspi1.Init.CLKPolarity = SPI_POLARITY_LOW;
  hspi1.Init.CLKPhase = SPI_PHASE_1EDGE;
  hspi1.Init.NSS = SPI_NSS_SOFT;
  hspi1.Init.BaudRatePrescaler = SPI_BAUDRATEPRESCALER_4;
  hspi1.Init.FirstBit = SPI_FIRSTBIT_MSB;
  hspi1.Init.TIMode = SPI_TIMODE_DISABLE;
  hspi1.Init.CRCCalculation = SPI_CRCCALCULATION_DISABLE;
  hspi1.Init.CRCPolynomial = 7;
  hspi1.Init.CRCLength = SPI_CRC_LENGTH_DATASIZE;
  hspi1.Init.NSSPMode = SPI_NSS_PULSE_ENABLE;
  if (HAL_SPI_Init(&hspi1) != HAL_OK)
  {
    Error_Handler();
  }

}

static void MX_UART4_Init(void)
{

  huart4.Instance = UART4;
  huart4.Init.BaudRate = 115200;
  huart4.Init.WordLength = UART_WORDLENGTH_8B;
  huart4.Init.StopBits = UART_STOPBITS_1;
  huart4.Init.Parity = UART_PARITY_NONE;
  huart4.Init.Mode = UART_MODE_TX_RX;
  huart4.Init.HwFlowCtl = UART_HWCONTROL_NONE;
  huart4.Init.OverSampling = UART_OVERSAMPLING_16;
  huart4.Init.OneBitSampling = UART_ONE_BIT_SAMPLE_DISABLE;
  huart4.AdvancedInit.AdvFeatureInit = UART_ADVFEATURE_NO_INIT;
  if (HAL_UART_Init(&huart4) != HAL_OK)
  {
    Error_Handler();
  }

}

static void MX_USB_PCD_Init(void)
{

  hpcd_USB_FS.Instance = USB;
  hpcd_USB_FS.Init.dev_endpoints = 8;
  hpcd_USB_FS.Init.speed = PCD_SPEED_FULL;
  hpcd_USB_FS.Init.phy_itface = PCD_PHY_EMBEDDED;
  hpcd_USB_FS.Init.low_power_enable = DISABLE;
  hpcd_USB_FS.Init.battery_charging_enable = DISABLE;
  if (HAL_PCD_Init(&hpcd_USB_FS) != HAL_OK)
  {
    Error_Handler();
  }

}

static void MX_GPIO_Init(void)
{
  GPIO_InitTypeDef GPIO_InitStruct = {0};

  /* GPIO Ports Clock Enable */
  __HAL_RCC_GPIOE_CLK_ENABLE();
  __HAL_RCC_GPIOC_CLK_ENABLE();
  __HAL_RCC_GPIOF_CLK_ENABLE();
  __HAL_RCC_GPIOA_CLK_ENABLE();
  __HAL_RCC_GPIOB_CLK_ENABLE();

  /*Configure GPIO pin Output Level */
  HAL_GPIO_WritePin(GPIOE, CS_I2C_SPI_Pin|LD4_Pin|LD3_Pin|LD5_Pin
                          |LD7_Pin|LD9_Pin|LD10_Pin|LD8_Pin
                          |LD6_Pin, GPIO_PIN_RESET);

  /*Configure GPIO pins : DRDY_Pin MEMS_INT3_Pin MEMS_INT4_Pin MEMS_INT1_Pin
                           MEMS_INT2_Pin */
  GPIO_InitStruct.Pin = DRDY_Pin|MEMS_INT3_Pin|MEMS_INT4_Pin|MEMS_INT1_Pin
                          |MEMS_INT2_Pin;
  GPIO_InitStruct.Mode = GPIO_MODE_EVT_RISING;
  GPIO_InitStruct.Pull = GPIO_NOPULL;
  HAL_GPIO_Init(GPIOE, &GPIO_InitStruct);

  /*Configure GPIO pins : CS_I2C_SPI_Pin LD4_Pin LD3_Pin LD5_Pin
                           LD7_Pin LD9_Pin LD10_Pin LD8_Pin
                           LD6_Pin */
  GPIO_InitStruct.Pin = CS_I2C_SPI_Pin|LD4_Pin|LD3_Pin|LD5_Pin
                          |LD7_Pin|LD9_Pin|LD10_Pin|LD8_Pin
                          |LD6_Pin;
  GPIO_InitStruct.Mode = GPIO_MODE_OUTPUT_PP;
  GPIO_InitStruct.Pull = GPIO_NOPULL;
  GPIO_InitStruct.Speed = GPIO_SPEED_FREQ_LOW;
  HAL_GPIO_Init(GPIOE, &GPIO_InitStruct);

  /*Configure GPIO pin : B1_Pin */
  GPIO_InitStruct.Pin = B1_Pin;
  GPIO_InitStruct.Mode = GPIO_MODE_INPUT;
  GPIO_InitStruct.Pull = GPIO_NOPULL;
  HAL_GPIO_Init(B1_GPIO_Port, &GPIO_InitStruct);

}

void Error_Handler(void)
{
  __disable_irq();
  while (1)
  {
  }
}
